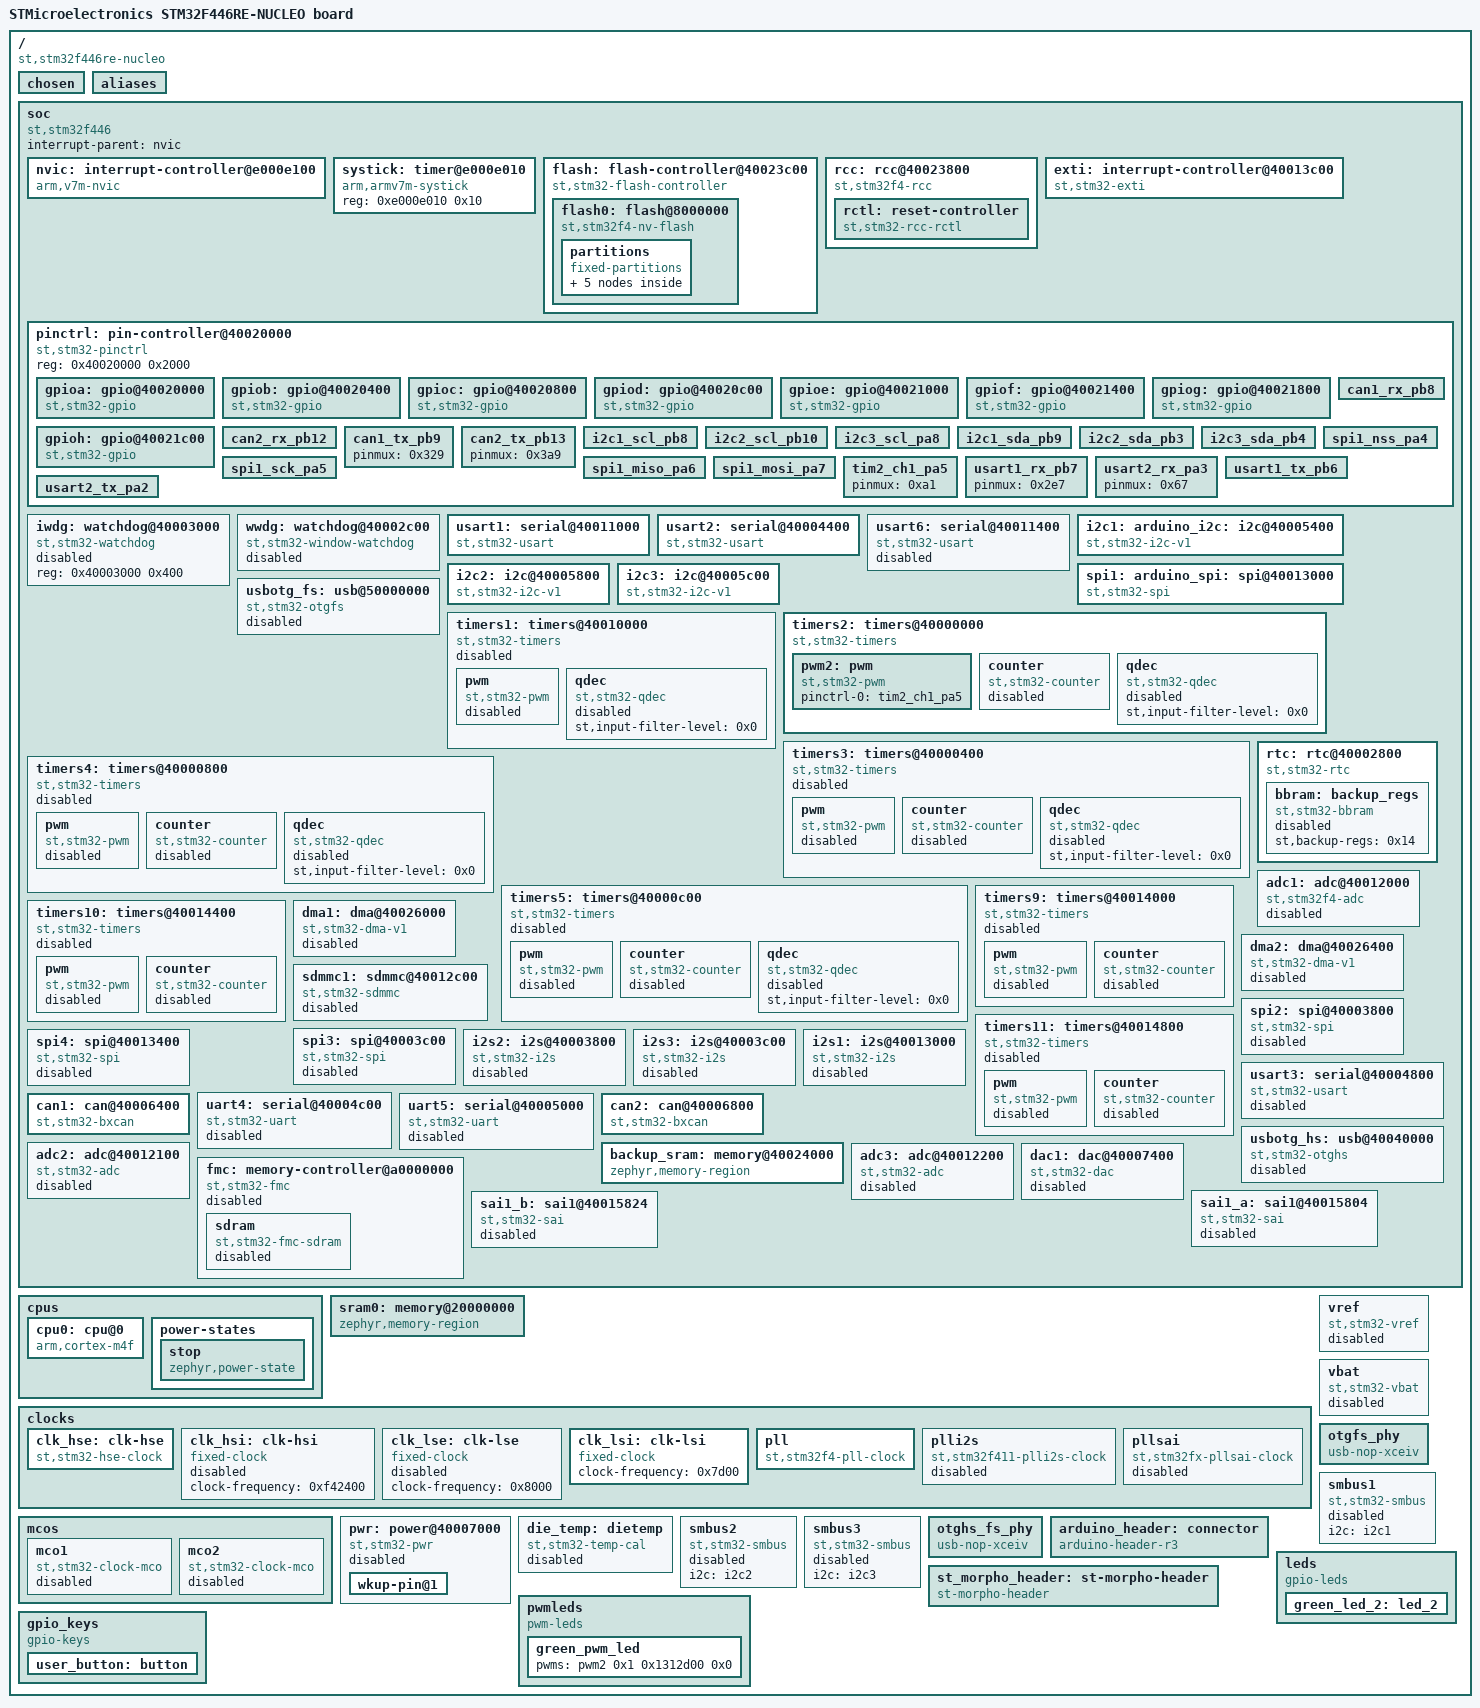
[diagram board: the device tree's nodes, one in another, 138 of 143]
/dts-v1/;

/* node '/' defined in zephyr\dts\common\skeleton.dtsi:9 */
/ {
	#address-cells = < 0x1 >;                              /* in zephyr\dts\common\skeleton.dtsi:10 */
	#size-cells = < 0x1 >;                                 /* in zephyr\dts\common\skeleton.dtsi:11 */
	model = "STMicroelectronics STM32F446RE-NUCLEO board"; /* in zephyr\boards\st\nucleo_f446re\nucleo_f446re.dts:15 */
	compatible = "st,stm32f446re-nucleo";                  /* in zephyr\boards\st\nucleo_f446re\nucleo_f446re.dts:16 */

	/* node '/chosen' defined in zephyr\dts\common\skeleton.dtsi:13 */
	chosen {
		zephyr,flash-controller = &flash;  /* in zephyr\dts\arm\st\f4\stm32f4.dtsi:27 */
		zephyr,cortex-m-idle-timer = &rtc; /* in zephyr\dts\arm\st\f4\stm32f4.dtsi:28 */
		zephyr,console = &usart2;          /* in zephyr\boards\st\nucleo_f446re\nucleo_f446re.dts:19 */
		zephyr,shell-uart = &usart2;       /* in zephyr\boards\st\nucleo_f446re\nucleo_f446re.dts:20 */
		zephyr,sram = &sram0;              /* in zephyr\boards\st\nucleo_f446re\nucleo_f446re.dts:21 */
		zephyr,flash = &flash0;            /* in zephyr\boards\st\nucleo_f446re\nucleo_f446re.dts:22 */
		zephyr,canbus = &can2;             /* in zephyr\boards\st\nucleo_f446re\nucleo_f446re.dts:23 */
	};

	/* node '/aliases' defined in zephyr\dts\common\skeleton.dtsi:15 */
	aliases {
		led0 = &green_led_2;       /* in zephyr\boards\st\nucleo_f446re\nucleo_f446re.dts:54 */
		pwm-led0 = &green_pwm_led; /* in zephyr\boards\st\nucleo_f446re\nucleo_f446re.dts:55 */
		sw0 = &user_button;        /* in zephyr\boards\st\nucleo_f446re\nucleo_f446re.dts:56 */
	};

	/* node '/soc' defined in zephyr\dts\arm\armv7-m.dtsi:6 */
	soc {
		#address-cells = < 0x1 >;     /* in zephyr\dts\arm\armv7-m.dtsi:7 */
		#size-cells = < 0x1 >;        /* in zephyr\dts\arm\armv7-m.dtsi:8 */
		interrupt-parent = < &nvic >; /* in zephyr\dts\arm\armv7-m.dtsi:10 */
		ranges;                       /* in zephyr\dts\arm\armv7-m.dtsi:11 */
		compatible = "st,stm32f446",
		             "st,stm32f4",
		             "simple-bus";    /* in zephyr\dts\arm\st\f4\stm32f446.dtsi:26 */

		/* node '/soc/interrupt-controller@e000e100' defined in zephyr\dts\arm\armv7-m.dtsi:13 */
		nvic: interrupt-controller@e000e100 {
			#address-cells = < 0x1 >;            /* in zephyr\dts\arm\armv7-m.dtsi:14 */
			compatible = "arm,v7m-nvic";         /* in zephyr\dts\arm\armv7-m.dtsi:15 */
			reg = < 0xe000e100 0xc00 >;          /* in zephyr\dts\arm\armv7-m.dtsi:16 */
			interrupt-controller;                /* in zephyr\dts\arm\armv7-m.dtsi:17 */
			#interrupt-cells = < 0x2 >;          /* in zephyr\dts\arm\armv7-m.dtsi:18 */
			arm,num-irq-priority-bits = < 0x4 >; /* in zephyr\dts\arm\st\f4\stm32f4.dtsi:676 */
			phandle = < 0x1 >;                   /* in zephyr\dts\arm\armv7-m.dtsi:10 */
		};

		/* node '/soc/timer@e000e010' defined in zephyr\dts\arm\armv7-m.dtsi:21 */
		systick: timer@e000e010 {
			compatible = "arm,armv7m-systick"; /* in zephyr\dts\arm\armv7-m.dtsi:22 */
			reg = < 0xe000e010 0x10 >;         /* in zephyr\dts\arm\armv7-m.dtsi:23 */
		};

		/* node '/soc/flash-controller@40023c00' defined in zephyr\dts\arm\st\f4\stm32f4.dtsi:111 */
		flash: flash-controller@40023c00 {
			compatible = "st,stm32-flash-controller",
			             "st,stm32f4-flash-controller"; /* in zephyr\dts\arm\st\f4\stm32f4.dtsi:112 */
			reg = < 0x40023c00 0x400 >;                 /* in zephyr\dts\arm\st\f4\stm32f4.dtsi:113 */
			interrupts = < 0x4 0x0 >;                   /* in zephyr\dts\arm\st\f4\stm32f4.dtsi:114 */
			#address-cells = < 0x1 >;                   /* in zephyr\dts\arm\st\f4\stm32f4.dtsi:116 */
			#size-cells = < 0x1 >;                      /* in zephyr\dts\arm\st\f4\stm32f4.dtsi:117 */

			/* node '/soc/flash-controller@40023c00/flash@8000000' defined in zephyr\dts\arm\st\f4\stm32f4.dtsi:119 */
			flash0: flash@8000000 {
				compatible = "st,stm32f4-nv-flash",
				             "st,stm32-nv-flash",
				             "soc-nv-flash";        /* in zephyr\dts\arm\st\f4\stm32f4.dtsi:120 */
				write-block-size = < 0x1 >;         /* in zephyr\dts\arm\st\f4\stm32f4.dtsi:123 */
				max-erase-time = < 0xfa0 >;         /* in zephyr\dts\arm\st\f4\stm32f4.dtsi:125 */
				reg = < 0x8000000 0x80000 >;        /* in zephyr\dts\arm\st\f4\stm32f446Xe.dtsi:17 */

				/* node '/soc/flash-controller@40023c00/flash@8000000/partitions' defined in zephyr\boards\st\nucleo_f446re\nucleo_f446re.dts:163 */
				partitions {
					compatible = "fixed-partitions"; /* in zephyr\boards\st\nucleo_f446re\nucleo_f446re.dts:164 */
					#address-cells = < 0x1 >;        /* in zephyr\boards\st\nucleo_f446re\nucleo_f446re.dts:165 */
					#size-cells = < 0x1 >;           /* in zephyr\boards\st\nucleo_f446re\nucleo_f446re.dts:166 */

					/* node '/soc/flash-controller@40023c00/flash@8000000/partitions/partition@0' defined in zephyr\boards\st\nucleo_f446re\nucleo_f446re.dts:168 */
					boot_partition: partition@0 {
						label = "mcuboot";     /* in zephyr\boards\st\nucleo_f446re\nucleo_f446re.dts:169 */
						reg = < 0x0 0x10000 >; /* in zephyr\boards\st\nucleo_f446re\nucleo_f446re.dts:170 */
						read-only;             /* in zephyr\boards\st\nucleo_f446re\nucleo_f446re.dts:171 */
					};

					/* node '/soc/flash-controller@40023c00/flash@8000000/partitions/partition@10000' defined in zephyr\boards\st\nucleo_f446re\nucleo_f446re.dts:179 */
					storage_partition: partition@10000 {
						label = "storage";         /* in zephyr\boards\st\nucleo_f446re\nucleo_f446re.dts:180 */
						reg = < 0x10000 0x10000 >; /* in zephyr\boards\st\nucleo_f446re\nucleo_f446re.dts:181 */
					};

					/* node '/soc/flash-controller@40023c00/flash@8000000/partitions/partition@20000' defined in zephyr\boards\st\nucleo_f446re\nucleo_f446re.dts:184 */
					slot0_partition: partition@20000 {
						label = "image-0";         /* in zephyr\boards\st\nucleo_f446re\nucleo_f446re.dts:185 */
						reg = < 0x20000 0x20000 >; /* in zephyr\boards\st\nucleo_f446re\nucleo_f446re.dts:186 */
					};

					/* node '/soc/flash-controller@40023c00/flash@8000000/partitions/partition@40000' defined in zephyr\boards\st\nucleo_f446re\nucleo_f446re.dts:189 */
					slot1_partition: partition@40000 {
						label = "image-1";         /* in zephyr\boards\st\nucleo_f446re\nucleo_f446re.dts:190 */
						reg = < 0x40000 0x20000 >; /* in zephyr\boards\st\nucleo_f446re\nucleo_f446re.dts:191 */
					};

					/* node '/soc/flash-controller@40023c00/flash@8000000/partitions/partition@60000' defined in zephyr\boards\st\nucleo_f446re\nucleo_f446re.dts:194 */
					scratch_partition: partition@60000 {
						label = "image-scratch";   /* in zephyr\boards\st\nucleo_f446re\nucleo_f446re.dts:195 */
						reg = < 0x60000 0x20000 >; /* in zephyr\boards\st\nucleo_f446re\nucleo_f446re.dts:196 */
					};
				};
			};
		};

		/* node '/soc/rcc@40023800' defined in zephyr\dts\arm\st\f4\stm32f4.dtsi:129 */
		rcc: rcc@40023800 {
			compatible = "st,stm32f4-rcc";   /* in zephyr\dts\arm\st\f4\stm32f4.dtsi:130 */
			#clock-cells = < 0x2 >;          /* in zephyr\dts\arm\st\f4\stm32f4.dtsi:131 */
			reg = < 0x40023800 0x400 >;      /* in zephyr\dts\arm\st\f4\stm32f4.dtsi:132 */
			clocks = < &pll >;               /* in agent\nucleo_f446re.overlay:18 */
			clock-frequency = < 0xaba9500 >; /* in agent\nucleo_f446re.overlay:20 */
			ahb-prescaler = < 0x1 >;         /* in agent\nucleo_f446re.overlay:23 */
			apb1-prescaler = < 0x4 >;        /* in agent\nucleo_f446re.overlay:24 */
			apb2-prescaler = < 0x2 >;        /* in agent\nucleo_f446re.overlay:25 */
			phandle = < 0x3 >;               /* in zephyr\dts\arm\st\f4\stm32f4.dtsi:146 */

			/* node '/soc/rcc@40023800/reset-controller' defined in zephyr\dts\arm\st\f4\stm32f4.dtsi:134 */
			rctl: reset-controller {
				compatible = "st,stm32-rcc-rctl"; /* in zephyr\dts\arm\st\f4\stm32f4.dtsi:135 */
				#reset-cells = < 0x1 >;           /* in zephyr\dts\arm\st\f4\stm32f4.dtsi:136 */
				phandle = < 0x4 >;                /* in zephyr\dts\arm\st\f4\stm32f4.dtsi:245 */
			};
		};

		/* node '/soc/interrupt-controller@40013c00' defined in zephyr\dts\arm\st\f4\stm32f4.dtsi:140 */
		exti: interrupt-controller@40013c00 {
			compatible = "st,stm32-exti";  /* in zephyr\dts\arm\st\f4\stm32f4.dtsi:141 */
			interrupt-controller;          /* in zephyr\dts\arm\st\f4\stm32f4.dtsi:142 */
			#interrupt-cells = < 0x1 >;    /* in zephyr\dts\arm\st\f4\stm32f4.dtsi:143 */
			#address-cells = < 0x0 >;      /* in zephyr\dts\arm\st\f4\stm32f4.dtsi:144 */
			reg = < 0x40013c00 0x400 >;    /* in zephyr\dts\arm\st\f4\stm32f4.dtsi:145 */
			clocks = < &rcc 0x44 0x4000 >; /* in zephyr\dts\arm\st\f4\stm32f4.dtsi:146 */
			num-lines = < 0x20 >;          /* in zephyr\dts\arm\st\f4\stm32f4.dtsi:147 */
			interrupts = < 0x6 0x0 >,
			             < 0x7 0x0 >,
			             < 0x8 0x0 >,
			             < 0x9 0x0 >,
			             < 0xa 0x0 >,
			             < 0x17 0x0 >,
			             < 0x28 0x0 >;     /* in zephyr\dts\arm\st\f4\stm32f4.dtsi:148 */
			interrupt-names = "line0",
			                  "line1",
			                  "line2",
			                  "line3",
			                  "line4",
			                  "line5-9",
			                  "line10-15"; /* in zephyr\dts\arm\st\f4\stm32f4.dtsi:150 */
			line-ranges = < 0x0 0x1 >,
			              < 0x1 0x1 >,
			              < 0x2 0x1 >,
			              < 0x3 0x1 >,
			              < 0x4 0x1 >,
			              < 0x5 0x5 >,
			              < 0xa 0x6 >;     /* in zephyr\dts\arm\st\f4\stm32f4.dtsi:152 */
		};

		/* node '/soc/pin-controller@40020000' defined in zephyr\dts\arm\st\f4\stm32f4.dtsi:156 */
		pinctrl: pin-controller@40020000 {
			compatible = "st,stm32-pinctrl"; /* in zephyr\dts\arm\st\f4\stm32f4.dtsi:157 */
			#address-cells = < 0x1 >;        /* in zephyr\dts\arm\st\f4\stm32f4.dtsi:158 */
			#size-cells = < 0x1 >;           /* in zephyr\dts\arm\st\f4\stm32f4.dtsi:159 */
			reg = < 0x40020000 0x2000 >;     /* in zephyr\dts\arm\st\f4\stm32f4.dtsi:160 */

			/* node '/soc/pin-controller@40020000/gpio@40020000' defined in zephyr\dts\arm\st\f4\stm32f4.dtsi:162 */
			gpioa: gpio@40020000 {
				compatible = "st,stm32-gpio"; /* in zephyr\dts\arm\st\f4\stm32f4.dtsi:163 */
				gpio-controller;              /* in zephyr\dts\arm\st\f4\stm32f4.dtsi:164 */
				#gpio-cells = < 0x2 >;        /* in zephyr\dts\arm\st\f4\stm32f4.dtsi:165 */
				reg = < 0x40020000 0x400 >;   /* in zephyr\dts\arm\st\f4\stm32f4.dtsi:166 */
				clocks = < &rcc 0x30 0x1 >;   /* in zephyr\dts\arm\st\f4\stm32f4.dtsi:167 */
				phandle = < 0x1e >;           /* in zephyr\dts\arm\st\f4\stm32f4.dtsi:615 */
			};

			/* node '/soc/pin-controller@40020000/gpio@40020400' defined in zephyr\dts\arm\st\f4\stm32f4.dtsi:170 */
			gpiob: gpio@40020400 {
				compatible = "st,stm32-gpio"; /* in zephyr\dts\arm\st\f4\stm32f4.dtsi:171 */
				gpio-controller;              /* in zephyr\dts\arm\st\f4\stm32f4.dtsi:172 */
				#gpio-cells = < 0x2 >;        /* in zephyr\dts\arm\st\f4\stm32f4.dtsi:173 */
				reg = < 0x40020400 0x400 >;   /* in zephyr\dts\arm\st\f4\stm32f4.dtsi:174 */
				clocks = < &rcc 0x30 0x2 >;   /* in zephyr\dts\arm\st\f4\stm32f4.dtsi:175 */
				phandle = < 0x23 >;           /* in zephyr\boards\st\nucleo_f446re\arduino_r3_connector.dtsi:15 */
			};

			/* node '/soc/pin-controller@40020000/gpio@40020800' defined in zephyr\dts\arm\st\f4\stm32f4.dtsi:178 */
			gpioc: gpio@40020800 {
				compatible = "st,stm32-gpio"; /* in zephyr\dts\arm\st\f4\stm32f4.dtsi:179 */
				gpio-controller;              /* in zephyr\dts\arm\st\f4\stm32f4.dtsi:180 */
				#gpio-cells = < 0x2 >;        /* in zephyr\dts\arm\st\f4\stm32f4.dtsi:181 */
				reg = < 0x40020800 0x400 >;   /* in zephyr\dts\arm\st\f4\stm32f4.dtsi:182 */
				clocks = < &rcc 0x30 0x4 >;   /* in zephyr\dts\arm\st\f4\stm32f4.dtsi:183 */
				phandle = < 0x24 >;           /* in zephyr\boards\st\nucleo_f446re\arduino_r3_connector.dtsi:15 */
			};

			/* node '/soc/pin-controller@40020000/gpio@40020c00' defined in zephyr\dts\arm\st\f4\stm32f4.dtsi:186 */
			gpiod: gpio@40020c00 {
				compatible = "st,stm32-gpio"; /* in zephyr\dts\arm\st\f4\stm32f4.dtsi:187 */
				gpio-controller;              /* in zephyr\dts\arm\st\f4\stm32f4.dtsi:188 */
				#gpio-cells = < 0x2 >;        /* in zephyr\dts\arm\st\f4\stm32f4.dtsi:189 */
				reg = < 0x40020c00 0x400 >;   /* in zephyr\dts\arm\st\f4\stm32f4.dtsi:190 */
				clocks = < &rcc 0x30 0x8 >;   /* in zephyr\dts\arm\st\f4\stm32f4.dtsi:191 */
				phandle = < 0x25 >;           /* in zephyr\boards\st\nucleo_f446re\st_morpho_connector.dtsi:15 */
			};

			/* node '/soc/pin-controller@40020000/gpio@40021000' defined in zephyr\dts\arm\st\f4\stm32f4.dtsi:194 */
			gpioe: gpio@40021000 {
				compatible = "st,stm32-gpio"; /* in zephyr\dts\arm\st\f4\stm32f4.dtsi:195 */
				gpio-controller;              /* in zephyr\dts\arm\st\f4\stm32f4.dtsi:196 */
				#gpio-cells = < 0x2 >;        /* in zephyr\dts\arm\st\f4\stm32f4.dtsi:197 */
				reg = < 0x40021000 0x400 >;   /* in zephyr\dts\arm\st\f4\stm32f4.dtsi:198 */
				clocks = < &rcc 0x30 0x10 >;  /* in zephyr\dts\arm\st\f4\stm32f4.dtsi:199 */
			};

			/* node '/soc/pin-controller@40020000/gpio@40021400' defined in zephyr\dts\arm\st\f4\stm32f4.dtsi:202 */
			gpiof: gpio@40021400 {
				compatible = "st,stm32-gpio"; /* in zephyr\dts\arm\st\f4\stm32f4.dtsi:203 */
				gpio-controller;              /* in zephyr\dts\arm\st\f4\stm32f4.dtsi:204 */
				#gpio-cells = < 0x2 >;        /* in zephyr\dts\arm\st\f4\stm32f4.dtsi:205 */
				reg = < 0x40021400 0x400 >;   /* in zephyr\dts\arm\st\f4\stm32f4.dtsi:206 */
				clocks = < &rcc 0x30 0x20 >;  /* in zephyr\dts\arm\st\f4\stm32f4.dtsi:207 */
			};

			/* node '/soc/pin-controller@40020000/gpio@40021800' defined in zephyr\dts\arm\st\f4\stm32f4.dtsi:210 */
			gpiog: gpio@40021800 {
				compatible = "st,stm32-gpio"; /* in zephyr\dts\arm\st\f4\stm32f4.dtsi:211 */
				gpio-controller;              /* in zephyr\dts\arm\st\f4\stm32f4.dtsi:212 */
				#gpio-cells = < 0x2 >;        /* in zephyr\dts\arm\st\f4\stm32f4.dtsi:213 */
				reg = < 0x40021800 0x400 >;   /* in zephyr\dts\arm\st\f4\stm32f4.dtsi:214 */
				clocks = < &rcc 0x30 0x40 >;  /* in zephyr\dts\arm\st\f4\stm32f4.dtsi:215 */
			};

			/* node '/soc/pin-controller@40020000/gpio@40021c00' defined in zephyr\dts\arm\st\f4\stm32f4.dtsi:218 */
			gpioh: gpio@40021c00 {
				compatible = "st,stm32-gpio"; /* in zephyr\dts\arm\st\f4\stm32f4.dtsi:219 */
				gpio-controller;              /* in zephyr\dts\arm\st\f4\stm32f4.dtsi:220 */
				#gpio-cells = < 0x2 >;        /* in zephyr\dts\arm\st\f4\stm32f4.dtsi:221 */
				reg = < 0x40021c00 0x400 >;   /* in zephyr\dts\arm\st\f4\stm32f4.dtsi:222 */
				clocks = < &rcc 0x30 0x80 >;  /* in zephyr\dts\arm\st\f4\stm32f4.dtsi:223 */
				phandle = < 0x26 >;           /* in zephyr\boards\st\nucleo_f446re\st_morpho_connector.dtsi:15 */
			};

			/* node '/soc/pin-controller@40020000/can1_rx_pb8' defined in modules\hal\stm32\dts\st\f4\stm32f446r(c-e)tx-pinctrl.dtsi:384 */
			can1_rx_pb8: can1_rx_pb8 {
				pinmux = < 0x309 >; /* in modules\hal\stm32\dts\st\f4\stm32f446r(c-e)tx-pinctrl.dtsi:385 */
				bias-pull-up;       /* in modules\hal\stm32\dts\st\f4\stm32f446r(c-e)tx-pinctrl.dtsi:386 */
				phandle = < 0x17 >; /* in zephyr\boards\st\nucleo_f446re\nucleo_f446re.dts:151 */
			};

			/* node '/soc/pin-controller@40020000/can2_rx_pb12' defined in modules\hal\stm32\dts\st\f4\stm32f446r(c-e)tx-pinctrl.dtsi:394 */
			can2_rx_pb12: can2_rx_pb12 {
				pinmux = < 0x389 >; /* in modules\hal\stm32\dts\st\f4\stm32f446r(c-e)tx-pinctrl.dtsi:395 */
				bias-pull-up;       /* in modules\hal\stm32\dts\st\f4\stm32f446r(c-e)tx-pinctrl.dtsi:396 */
				phandle = < 0x19 >; /* in zephyr\boards\st\nucleo_f446re\nucleo_f446re.dts:157 */
			};

			/* node '/soc/pin-controller@40020000/can1_tx_pb9' defined in modules\hal\stm32\dts\st\f4\stm32f446r(c-e)tx-pinctrl.dtsi:405 */
			can1_tx_pb9: can1_tx_pb9 {
				pinmux = < 0x329 >; /* in modules\hal\stm32\dts\st\f4\stm32f446r(c-e)tx-pinctrl.dtsi:406 */
				phandle = < 0x18 >; /* in zephyr\boards\st\nucleo_f446re\nucleo_f446re.dts:151 */
			};

			/* node '/soc/pin-controller@40020000/can2_tx_pb13' defined in modules\hal\stm32\dts\st\f4\stm32f446r(c-e)tx-pinctrl.dtsi:413 */
			can2_tx_pb13: can2_tx_pb13 {
				pinmux = < 0x3a9 >; /* in modules\hal\stm32\dts\st\f4\stm32f446r(c-e)tx-pinctrl.dtsi:414 */
				phandle = < 0x1a >; /* in zephyr\boards\st\nucleo_f446re\nucleo_f446re.dts:157 */
			};

			/* node '/soc/pin-controller@40020000/i2c1_scl_pb8' defined in modules\hal\stm32\dts\st\f4\stm32f446r(c-e)tx-pinctrl.dtsi:522 */
			i2c1_scl_pb8: i2c1_scl_pb8 {
				pinmux = < 0x304 >; /* in modules\hal\stm32\dts\st\f4\stm32f446r(c-e)tx-pinctrl.dtsi:523 */
				bias-pull-up;       /* in modules\hal\stm32\dts\st\f4\stm32f446r(c-e)tx-pinctrl.dtsi:524 */
				drive-open-drain;   /* in modules\hal\stm32\dts\st\f4\stm32f446r(c-e)tx-pinctrl.dtsi:525 */
				phandle = < 0x9 >;  /* in zephyr\boards\st\nucleo_f446re\nucleo_f446re.dts:102 */
			};

			/* node '/soc/pin-controller@40020000/i2c2_scl_pb10' defined in modules\hal\stm32\dts\st\f4\stm32f446r(c-e)tx-pinctrl.dtsi:528 */
			i2c2_scl_pb10: i2c2_scl_pb10 {
				pinmux = < 0x344 >; /* in modules\hal\stm32\dts\st\f4\stm32f446r(c-e)tx-pinctrl.dtsi:529 */
				bias-pull-up;       /* in modules\hal\stm32\dts\st\f4\stm32f446r(c-e)tx-pinctrl.dtsi:530 */
				drive-open-drain;   /* in modules\hal\stm32\dts\st\f4\stm32f446r(c-e)tx-pinctrl.dtsi:531 */
				phandle = < 0xb >;  /* in zephyr\boards\st\nucleo_f446re\nucleo_f446re.dts:109 */
			};

			/* node '/soc/pin-controller@40020000/i2c3_scl_pa8' defined in modules\hal\stm32\dts\st\f4\stm32f446r(c-e)tx-pinctrl.dtsi:534 */
			i2c3_scl_pa8: i2c3_scl_pa8 {
				pinmux = < 0x104 >; /* in modules\hal\stm32\dts\st\f4\stm32f446r(c-e)tx-pinctrl.dtsi:535 */
				bias-pull-up;       /* in modules\hal\stm32\dts\st\f4\stm32f446r(c-e)tx-pinctrl.dtsi:536 */
				drive-open-drain;   /* in modules\hal\stm32\dts\st\f4\stm32f446r(c-e)tx-pinctrl.dtsi:537 */
				phandle = < 0xd >;  /* in zephyr\boards\st\nucleo_f446re\nucleo_f446re.dts:116 */
			};

			/* node '/soc/pin-controller@40020000/i2c1_sda_pb9' defined in modules\hal\stm32\dts\st\f4\stm32f446r(c-e)tx-pinctrl.dtsi:548 */
			i2c1_sda_pb9: i2c1_sda_pb9 {
				pinmux = < 0x324 >; /* in modules\hal\stm32\dts\st\f4\stm32f446r(c-e)tx-pinctrl.dtsi:549 */
				bias-pull-up;       /* in modules\hal\stm32\dts\st\f4\stm32f446r(c-e)tx-pinctrl.dtsi:550 */
				drive-open-drain;   /* in modules\hal\stm32\dts\st\f4\stm32f446r(c-e)tx-pinctrl.dtsi:551 */
				phandle = < 0xa >;  /* in zephyr\boards\st\nucleo_f446re\nucleo_f446re.dts:102 */
			};

			/* node '/soc/pin-controller@40020000/i2c2_sda_pb3' defined in modules\hal\stm32\dts\st\f4\stm32f446r(c-e)tx-pinctrl.dtsi:554 */
			i2c2_sda_pb3: i2c2_sda_pb3 {
				pinmux = < 0x264 >; /* in modules\hal\stm32\dts\st\f4\stm32f446r(c-e)tx-pinctrl.dtsi:555 */
				bias-pull-up;       /* in modules\hal\stm32\dts\st\f4\stm32f446r(c-e)tx-pinctrl.dtsi:556 */
				drive-open-drain;   /* in modules\hal\stm32\dts\st\f4\stm32f446r(c-e)tx-pinctrl.dtsi:557 */
				phandle = < 0xc >;  /* in zephyr\boards\st\nucleo_f446re\nucleo_f446re.dts:109 */
			};

			/* node '/soc/pin-controller@40020000/i2c3_sda_pb4' defined in modules\hal\stm32\dts\st\f4\stm32f446r(c-e)tx-pinctrl.dtsi:566 */
			i2c3_sda_pb4: i2c3_sda_pb4 {
				pinmux = < 0x284 >; /* in modules\hal\stm32\dts\st\f4\stm32f446r(c-e)tx-pinctrl.dtsi:567 */
				bias-pull-up;       /* in modules\hal\stm32\dts\st\f4\stm32f446r(c-e)tx-pinctrl.dtsi:568 */
				drive-open-drain;   /* in modules\hal\stm32\dts\st\f4\stm32f446r(c-e)tx-pinctrl.dtsi:569 */
				phandle = < 0xe >;  /* in zephyr\boards\st\nucleo_f446re\nucleo_f446re.dts:116 */
			};

			/* node '/soc/pin-controller@40020000/spi1_miso_pa6' defined in modules\hal\stm32\dts\st\f4\stm32f446r(c-e)tx-pinctrl.dtsi:913 */
			spi1_miso_pa6: spi1_miso_pa6 {
				pinmux = < 0xc5 >;  /* in modules\hal\stm32\dts\st\f4\stm32f446r(c-e)tx-pinctrl.dtsi:914 */
				bias-pull-down;     /* in modules\hal\stm32\dts\st\f4\stm32f446r(c-e)tx-pinctrl.dtsi:915 */
				phandle = < 0x11 >; /* in zephyr\boards\st\nucleo_f446re\nucleo_f446re.dts:123 */
			};

			/* node '/soc/pin-controller@40020000/spi1_mosi_pa7' defined in modules\hal\stm32\dts\st\f4\stm32f446r(c-e)tx-pinctrl.dtsi:945 */
			spi1_mosi_pa7: spi1_mosi_pa7 {
				pinmux = < 0xe5 >;  /* in modules\hal\stm32\dts\st\f4\stm32f446r(c-e)tx-pinctrl.dtsi:946 */
				bias-pull-down;     /* in modules\hal\stm32\dts\st\f4\stm32f446r(c-e)tx-pinctrl.dtsi:947 */
				phandle = < 0x12 >; /* in zephyr\boards\st\nucleo_f446re\nucleo_f446re.dts:123 */
			};

			/* node '/soc/pin-controller@40020000/spi1_nss_pa4' defined in modules\hal\stm32\dts\st\f4\stm32f446r(c-e)tx-pinctrl.dtsi:997 */
			spi1_nss_pa4: spi1_nss_pa4 {
				pinmux = < 0x85 >; /* in modules\hal\stm32\dts\st\f4\stm32f446r(c-e)tx-pinctrl.dtsi:998 */
				bias-pull-up;      /* in modules\hal\stm32\dts\st\f4\stm32f446r(c-e)tx-pinctrl.dtsi:999 */
				phandle = < 0xf >; /* in zephyr\boards\st\nucleo_f446re\nucleo_f446re.dts:123 */
			};

			/* node '/soc/pin-controller@40020000/spi1_sck_pa5' defined in modules\hal\stm32\dts\st\f4\stm32f446r(c-e)tx-pinctrl.dtsi:1034 */
			spi1_sck_pa5: spi1_sck_pa5 {
				pinmux = < 0xa5 >;             /* in modules\hal\stm32\dts\st\f4\stm32f446r(c-e)tx-pinctrl.dtsi:1035 */
				bias-pull-down;                /* in modules\hal\stm32\dts\st\f4\stm32f446r(c-e)tx-pinctrl.dtsi:1036 */
				slew-rate = "very-high-speed"; /* in modules\hal\stm32\dts\st\f4\stm32f446r(c-e)tx-pinctrl.dtsi:1037 */
				phandle = < 0x10 >;            /* in zephyr\boards\st\nucleo_f446re\nucleo_f446re.dts:123 */
			};

			/* node '/soc/pin-controller@40020000/tim2_ch1_pa5' defined in modules\hal\stm32\dts\st\f4\stm32f446r(c-e)tx-pinctrl.dtsi:1162 */
			tim2_ch1_pa5: tim2_ch1_pa5 {
				pinmux = < 0xa1 >;  /* in modules\hal\stm32\dts\st\f4\stm32f446r(c-e)tx-pinctrl.dtsi:1163 */
				phandle = < 0x14 >; /* in zephyr\boards\st\nucleo_f446re\nucleo_f446re.dts:134 */
			};

			/* node '/soc/pin-controller@40020000/usart1_rx_pb7' defined in modules\hal\stm32\dts\st\f4\stm32f446r(c-e)tx-pinctrl.dtsi:1386 */
			usart1_rx_pb7: usart1_rx_pb7 {
				pinmux = < 0x2e7 >; /* in modules\hal\stm32\dts\st\f4\stm32f446r(c-e)tx-pinctrl.dtsi:1387 */
				phandle = < 0x6 >;  /* in zephyr\boards\st\nucleo_f446re\nucleo_f446re.dts:88 */
			};

			/* node '/soc/pin-controller@40020000/usart2_rx_pa3' defined in modules\hal\stm32\dts\st\f4\stm32f446r(c-e)tx-pinctrl.dtsi:1390 */
			usart2_rx_pa3: usart2_rx_pa3 {
				pinmux = < 0x67 >; /* in modules\hal\stm32\dts\st\f4\stm32f446r(c-e)tx-pinctrl.dtsi:1391 */
				phandle = < 0x8 >; /* in zephyr\boards\st\nucleo_f446re\nucleo_f446re.dts:95 */
			};

			/* node '/soc/pin-controller@40020000/usart1_tx_pb6' defined in modules\hal\stm32\dts\st\f4\stm32f446r(c-e)tx-pinctrl.dtsi:1425 */
			usart1_tx_pb6: usart1_tx_pb6 {
				pinmux = < 0x2c7 >; /* in modules\hal\stm32\dts\st\f4\stm32f446r(c-e)tx-pinctrl.dtsi:1426 */
				bias-pull-up;       /* in modules\hal\stm32\dts\st\f4\stm32f446r(c-e)tx-pinctrl.dtsi:1427 */
				phandle = < 0x5 >;  /* in zephyr\boards\st\nucleo_f446re\nucleo_f446re.dts:88 */
			};

			/* node '/soc/pin-controller@40020000/usart2_tx_pa2' defined in modules\hal\stm32\dts\st\f4\stm32f446r(c-e)tx-pinctrl.dtsi:1430 */
			usart2_tx_pa2: usart2_tx_pa2 {
				pinmux = < 0x47 >; /* in modules\hal\stm32\dts\st\f4\stm32f446r(c-e)tx-pinctrl.dtsi:1431 */
				bias-pull-up;      /* in modules\hal\stm32\dts\st\f4\stm32f446r(c-e)tx-pinctrl.dtsi:1432 */
				phandle = < 0x7 >; /* in zephyr\boards\st\nucleo_f446re\nucleo_f446re.dts:95 */
			};
		};

		/* node '/soc/watchdog@40003000' defined in zephyr\dts\arm\st\f4\stm32f4.dtsi:227 */
		iwdg: watchdog@40003000 {
			compatible = "st,stm32-watchdog"; /* in zephyr\dts\arm\st\f4\stm32f4.dtsi:228 */
			reg = < 0x40003000 0x400 >;       /* in zephyr\dts\arm\st\f4\stm32f4.dtsi:229 */
			status = "disabled";              /* in zephyr\dts\arm\st\f4\stm32f4.dtsi:230 */
		};

		/* node '/soc/watchdog@40002c00' defined in zephyr\dts\arm\st\f4\stm32f4.dtsi:233 */
		wwdg: watchdog@40002c00 {
			compatible = "st,stm32-window-watchdog"; /* in zephyr\dts\arm\st\f4\stm32f4.dtsi:234 */
			reg = < 0x40002c00 0x400 >;              /* in zephyr\dts\arm\st\f4\stm32f4.dtsi:235 */
			clocks = < &rcc 0x40 0x800 >;            /* in zephyr\dts\arm\st\f4\stm32f4.dtsi:236 */
			interrupts = < 0x0 0x7 >;                /* in zephyr\dts\arm\st\f4\stm32f4.dtsi:237 */
			status = "disabled";                     /* in zephyr\dts\arm\st\f4\stm32f4.dtsi:238 */
		};

		/* node '/soc/serial@40011000' defined in zephyr\dts\arm\st\f4\stm32f4.dtsi:241 */
		usart1: serial@40011000 {
			compatible = "st,stm32-usart",
			             "st,stm32-uart";                  /* in zephyr\dts\arm\st\f4\stm32f4.dtsi:242 */
			reg = < 0x40011000 0x400 >;                    /* in zephyr\dts\arm\st\f4\stm32f4.dtsi:243 */
			clocks = < &rcc 0x44 0x10 >;                   /* in zephyr\dts\arm\st\f4\stm32f4.dtsi:244 */
			resets = < &rctl 0x484 >;                      /* in zephyr\dts\arm\st\f4\stm32f4.dtsi:245 */
			interrupts = < 0x25 0x0 >;                     /* in zephyr\dts\arm\st\f4\stm32f4.dtsi:246 */
			pinctrl-0 = < &usart1_tx_pb6 &usart1_rx_pb7 >; /* in zephyr\boards\st\nucleo_f446re\nucleo_f446re.dts:88 */
			pinctrl-names = "default";                     /* in zephyr\boards\st\nucleo_f446re\nucleo_f446re.dts:89 */
			current-speed = < 0x1c200 >;                   /* in zephyr\boards\st\nucleo_f446re\nucleo_f446re.dts:90 */
			status = "okay";                               /* in zephyr\boards\st\nucleo_f446re\nucleo_f446re.dts:91 */
		};

		/* node '/soc/serial@40004400' defined in zephyr\dts\arm\st\f4\stm32f4.dtsi:250 */
		usart2: serial@40004400 {
			compatible = "st,stm32-usart",
			             "st,stm32-uart";                  /* in zephyr\dts\arm\st\f4\stm32f4.dtsi:251 */
			reg = < 0x40004400 0x400 >;                    /* in zephyr\dts\arm\st\f4\stm32f4.dtsi:252 */
			clocks = < &rcc 0x40 0x20000 >;                /* in zephyr\dts\arm\st\f4\stm32f4.dtsi:253 */
			resets = < &rctl 0x411 >;                      /* in zephyr\dts\arm\st\f4\stm32f4.dtsi:254 */
			interrupts = < 0x26 0x0 >;                     /* in zephyr\dts\arm\st\f4\stm32f4.dtsi:255 */
			pinctrl-0 = < &usart2_tx_pa2 &usart2_rx_pa3 >; /* in zephyr\boards\st\nucleo_f446re\nucleo_f446re.dts:95 */
			pinctrl-names = "default";                     /* in zephyr\boards\st\nucleo_f446re\nucleo_f446re.dts:96 */
			current-speed = < 0x1c200 >;                   /* in zephyr\boards\st\nucleo_f446re\nucleo_f446re.dts:97 */
			status = "okay";                               /* in zephyr\boards\st\nucleo_f446re\nucleo_f446re.dts:98 */
		};

		/* node '/soc/serial@40011400' defined in zephyr\dts\arm\st\f4\stm32f4.dtsi:259 */
		usart6: serial@40011400 {
			compatible = "st,stm32-usart",
			             "st,stm32-uart";  /* in zephyr\dts\arm\st\f4\stm32f4.dtsi:260 */
			reg = < 0x40011400 0x400 >;    /* in zephyr\dts\arm\st\f4\stm32f4.dtsi:261 */
			clocks = < &rcc 0x44 0x20 >;   /* in zephyr\dts\arm\st\f4\stm32f4.dtsi:262 */
			resets = < &rctl 0x485 >;      /* in zephyr\dts\arm\st\f4\stm32f4.dtsi:263 */
			interrupts = < 0x47 0x0 >;     /* in zephyr\dts\arm\st\f4\stm32f4.dtsi:264 */
			status = "disabled";           /* in zephyr\dts\arm\st\f4\stm32f4.dtsi:265 */
		};

		/* node '/soc/i2c@40005400' defined in zephyr\dts\arm\st\f4\stm32f4.dtsi:268 */
		i2c1: arduino_i2c: i2c@40005400 {
			compatible = "st,stm32-i2c-v1";              /* in zephyr\dts\arm\st\f4\stm32f4.dtsi:269 */
			#address-cells = < 0x1 >;                    /* in zephyr\dts\arm\st\f4\stm32f4.dtsi:271 */
			#size-cells = < 0x0 >;                       /* in zephyr\dts\arm\st\f4\stm32f4.dtsi:272 */
			reg = < 0x40005400 0x400 >;                  /* in zephyr\dts\arm\st\f4\stm32f4.dtsi:273 */
			clocks = < &rcc 0x40 0x200000 >;             /* in zephyr\dts\arm\st\f4\stm32f4.dtsi:274 */
			interrupts = < 0x1f 0x0 >,
			             < 0x20 0x0 >;                   /* in zephyr\dts\arm\st\f4\stm32f4.dtsi:275 */
			interrupt-names = "event",
			                  "error";                   /* in zephyr\dts\arm\st\f4\stm32f4.dtsi:276 */
			pinctrl-0 = < &i2c1_scl_pb8 &i2c1_sda_pb9 >; /* in zephyr\boards\st\nucleo_f446re\nucleo_f446re.dts:102 */
			pinctrl-names = "default";                   /* in zephyr\boards\st\nucleo_f446re\nucleo_f446re.dts:103 */
			status = "okay";                             /* in zephyr\boards\st\nucleo_f446re\nucleo_f446re.dts:104 */
			clock-frequency = < 0x61a80 >;               /* in zephyr\boards\st\nucleo_f446re\nucleo_f446re.dts:105 */
			phandle = < 0x20 >;                          /* in zephyr\dts\arm\st\f4\stm32f4.dtsi:654 */
		};

		/* node '/soc/i2c@40005800' defined in zephyr\dts\arm\st\f4\stm32f4.dtsi:280 */
		i2c2: i2c@40005800 {
			compatible = "st,stm32-i2c-v1";               /* in zephyr\dts\arm\st\f4\stm32f4.dtsi:281 */
			#address-cells = < 0x1 >;                     /* in zephyr\dts\arm\st\f4\stm32f4.dtsi:283 */
			#size-cells = < 0x0 >;                        /* in zephyr\dts\arm\st\f4\stm32f4.dtsi:284 */
			reg = < 0x40005800 0x400 >;                   /* in zephyr\dts\arm\st\f4\stm32f4.dtsi:285 */
			clocks = < &rcc 0x40 0x400000 >;              /* in zephyr\dts\arm\st\f4\stm32f4.dtsi:286 */
			interrupts = < 0x21 0x0 >,
			             < 0x22 0x0 >;                    /* in zephyr\dts\arm\st\f4\stm32f4.dtsi:287 */
			interrupt-names = "event",
			                  "error";                    /* in zephyr\dts\arm\st\f4\stm32f4.dtsi:288 */
			pinctrl-0 = < &i2c2_scl_pb10 &i2c2_sda_pb3 >; /* in zephyr\boards\st\nucleo_f446re\nucleo_f446re.dts:109 */
			pinctrl-names = "default";                    /* in zephyr\boards\st\nucleo_f446re\nucleo_f446re.dts:110 */
			status = "okay";                              /* in zephyr\boards\st\nucleo_f446re\nucleo_f446re.dts:111 */
			clock-frequency = < 0x61a80 >;                /* in zephyr\boards\st\nucleo_f446re\nucleo_f446re.dts:112 */
			phandle = < 0x21 >;                           /* in zephyr\dts\arm\st\f4\stm32f4.dtsi:662 */
		};

		/* node '/soc/i2c@40005c00' defined in zephyr\dts\arm\st\f4\stm32f4.dtsi:292 */
		i2c3: i2c@40005c00 {
			compatible = "st,stm32-i2c-v1";              /* in zephyr\dts\arm\st\f4\stm32f4.dtsi:293 */
			#address-cells = < 0x1 >;                    /* in zephyr\dts\arm\st\f4\stm32f4.dtsi:295 */
			#size-cells = < 0x0 >;                       /* in zephyr\dts\arm\st\f4\stm32f4.dtsi:296 */
			reg = < 0x40005c00 0x400 >;                  /* in zephyr\dts\arm\st\f4\stm32f4.dtsi:297 */
			clocks = < &rcc 0x40 0x800000 >;             /* in zephyr\dts\arm\st\f4\stm32f4.dtsi:298 */
			interrupts = < 0x48 0x0 >,
			             < 0x49 0x0 >;                   /* in zephyr\dts\arm\st\f4\stm32f4.dtsi:299 */
			interrupt-names = "event",
			                  "error";                   /* in zephyr\dts\arm\st\f4\stm32f4.dtsi:300 */
			pinctrl-0 = < &i2c3_scl_pa8 &i2c3_sda_pb4 >; /* in zephyr\boards\st\nucleo_f446re\nucleo_f446re.dts:116 */
			pinctrl-names = "default";                   /* in zephyr\boards\st\nucleo_f446re\nucleo_f446re.dts:117 */
			status = "okay";                             /* in zephyr\boards\st\nucleo_f446re\nucleo_f446re.dts:118 */
			clock-frequency = < 0x61a80 >;               /* in zephyr\boards\st\nucleo_f446re\nucleo_f446re.dts:119 */
			phandle = < 0x22 >;                          /* in zephyr\dts\arm\st\f4\stm32f4.dtsi:670 */
		};

		/* node '/soc/spi@40013000' defined in zephyr\dts\arm\st\f4\stm32f4.dtsi:304 */
		spi1: arduino_spi: spi@40013000 {
			compatible = "st,stm32-spi";                                               /* in zephyr\dts\arm\st\f4\stm32f4.dtsi:305 */
			#address-cells = < 0x1 >;                                                  /* in zephyr\dts\arm\st\f4\stm32f4.dtsi:306 */
			#size-cells = < 0x0 >;                                                     /* in zephyr\dts\arm\st\f4\stm32f4.dtsi:307 */
			reg = < 0x40013000 0x400 >;                                                /* in zephyr\dts\arm\st\f4\stm32f4.dtsi:308 */
			clocks = < &rcc 0x44 0x1000 >;                                             /* in zephyr\dts\arm\st\f4\stm32f4.dtsi:309 */
			interrupts = < 0x23 0x5 >;                                                 /* in zephyr\dts\arm\st\f4\stm32f4.dtsi:310 */
			pinctrl-0 = < &spi1_nss_pa4 &spi1_sck_pa5 &spi1_miso_pa6 &spi1_mosi_pa7 >; /* in zephyr\boards\st\nucleo_f446re\nucleo_f446re.dts:123 */
			pinctrl-names = "default";                                                 /* in zephyr\boards\st\nucleo_f446re\nucleo_f446re.dts:125 */
			status = "okay";                                                           /* in zephyr\boards\st\nucleo_f446re\nucleo_f446re.dts:126 */
		};

		/* node '/soc/usb@50000000' defined in zephyr\dts\arm\st\f4\stm32f4.dtsi:314 */
		usbotg_fs: usb@50000000 {
			compatible = "st,stm32-otgfs";  /* in zephyr\dts\arm\st\f4\stm32f4.dtsi:315 */
			reg = < 0x50000000 0x40000 >;   /* in zephyr\dts\arm\st\f4\stm32f4.dtsi:316 */
			interrupts = < 0x43 0x0 >;      /* in zephyr\dts\arm\st\f4\stm32f4.dtsi:317 */
			interrupt-names = "otgfs";      /* in zephyr\dts\arm\st\f4\stm32f4.dtsi:318 */
			ram-size = < 0x500 >;           /* in zephyr\dts\arm\st\f4\stm32f4.dtsi:320 */
			maximum-speed = "full-speed";   /* in zephyr\dts\arm\st\f4\stm32f4.dtsi:321 */
			phys = < &otgfs_phy >;          /* in zephyr\dts\arm\st\f4\stm32f4.dtsi:322 */
			status = "disabled";            /* in zephyr\dts\arm\st\f4\stm32f4.dtsi:325 */
			num-bidir-endpoints = < 0x6 >;  /* in zephyr\dts\arm\st\f4\stm32f446.dtsi:89 */
			clocks = < &rcc 0x34 0x80 >,
			         < &rcc 0x7 0x1b0094 >; /* in zephyr\dts\arm\st\f4\stm32f446.dtsi:90 */
		};

		/* node '/soc/timers@40010000' defined in zephyr\dts\arm\st\f4\stm32f4.dtsi:328 */
		timers1: timers@40010000 {
			compatible = "st,stm32-timers"; /* in zephyr\dts\arm\st\f4\stm32f4.dtsi:329 */
			reg = < 0x40010000 0x400 >;     /* in zephyr\dts\arm\st\f4\stm32f4.dtsi:330 */
			clocks = < &rcc 0x44 0x1 >,
			         < &rcc 0xd 0xff >;     /* in zephyr\dts\arm\st\f4\stm32f4.dtsi:331 */
			resets = < &rctl 0x480 >;       /* in zephyr\dts\arm\st\f4\stm32f4.dtsi:333 */
			interrupts = < 0x18 0x0 >,
			             < 0x19 0x0 >,
			             < 0x1a 0x0 >,
			             < 0x1b 0x0 >;      /* in zephyr\dts\arm\st\f4\stm32f4.dtsi:334 */
			interrupt-names = "brk",
			                  "up",
			                  "trgcom",
			                  "cc";         /* in zephyr\dts\arm\st\f4\stm32f4.dtsi:335 */
			st,prescaler = < 0x0 >;         /* in zephyr\dts\arm\st\f4\stm32f4.dtsi:336 */
			status = "disabled";            /* in zephyr\dts\arm\st\f4\stm32f4.dtsi:337 */

			/* node '/soc/timers@40010000/pwm' defined in zephyr\dts\arm\st\f4\stm32f4.dtsi:339 */
			pwm {
				compatible = "st,stm32-pwm"; /* in zephyr\dts\arm\st\f4\stm32f4.dtsi:340 */
				status = "disabled";         /* in zephyr\dts\arm\st\f4\stm32f4.dtsi:341 */
				#pwm-cells = < 0x3 >;        /* in zephyr\dts\arm\st\f4\stm32f4.dtsi:342 */
			};

			/* node '/soc/timers@40010000/qdec' defined in zephyr\dts\arm\st\f4\stm32f4.dtsi:345 */
			qdec {
				compatible = "st,stm32-qdec";    /* in zephyr\dts\arm\st\f4\stm32f4.dtsi:346 */
				st,input-filter-level = < 0x0 >; /* in zephyr\dts\arm\st\f4\stm32f4.dtsi:347 */
				status = "disabled";             /* in zephyr\dts\arm\st\f4\stm32f4.dtsi:348 */
			};
		};

		/* node '/soc/timers@40000000' defined in zephyr\dts\arm\st\f4\stm32f4.dtsi:352 */
		timers2: timers@40000000 {
			compatible = "st,stm32-timers"; /* in zephyr\dts\arm\st\f4\stm32f4.dtsi:353 */
			reg = < 0x40000000 0x400 >;     /* in zephyr\dts\arm\st\f4\stm32f4.dtsi:354 */
			clocks = < &rcc 0x40 0x1 >,
			         < &rcc 0xc 0xff >;     /* in zephyr\dts\arm\st\f4\stm32f4.dtsi:355 */
			resets = < &rctl 0x400 >;       /* in zephyr\dts\arm\st\f4\stm32f4.dtsi:357 */
			interrupts = < 0x1c 0x0 >;      /* in zephyr\dts\arm\st\f4\stm32f4.dtsi:358 */
			interrupt-names = "global";     /* in zephyr\dts\arm\st\f4\stm32f4.dtsi:359 */
			st,prescaler = < 0x0 >;         /* in zephyr\dts\arm\st\f4\stm32f4.dtsi:360 */
			status = "okay";                /* in zephyr\boards\st\nucleo_f446re\nucleo_f446re.dts:130 */

			/* node '/soc/timers@40000000/pwm' defined in zephyr\dts\arm\st\f4\stm32f4.dtsi:363 */
			pwm2: pwm {
				compatible = "st,stm32-pwm";   /* in zephyr\dts\arm\st\f4\stm32f4.dtsi:364 */
				#pwm-cells = < 0x3 >;          /* in zephyr\dts\arm\st\f4\stm32f4.dtsi:366 */
				status = "okay";               /* in zephyr\boards\st\nucleo_f446re\nucleo_f446re.dts:133 */
				pinctrl-0 = < &tim2_ch1_pa5 >; /* in zephyr\boards\st\nucleo_f446re\nucleo_f446re.dts:134 */
				pinctrl-names = "default";     /* in zephyr\boards\st\nucleo_f446re\nucleo_f446re.dts:135 */
				phandle = < 0x27 >;            /* in zephyr\boards\st\nucleo_f446re\nucleo_f446re.dts:39 */
			};

			/* node '/soc/timers@40000000/counter' defined in zephyr\dts\arm\st\f4\stm32f4.dtsi:369 */
			counter {
				compatible = "st,stm32-counter"; /* in zephyr\dts\arm\st\f4\stm32f4.dtsi:370 */
				status = "disabled";             /* in zephyr\dts\arm\st\f4\stm32f4.dtsi:371 */
			};

			/* node '/soc/timers@40000000/qdec' defined in zephyr\dts\arm\st\f4\stm32f4.dtsi:374 */
			qdec {
				compatible = "st,stm32-qdec";    /* in zephyr\dts\arm\st\f4\stm32f4.dtsi:375 */
				st,input-filter-level = < 0x0 >; /* in zephyr\dts\arm\st\f4\stm32f4.dtsi:376 */
				status = "disabled";             /* in zephyr\dts\arm\st\f4\stm32f4.dtsi:377 */
			};
		};

		/* node '/soc/timers@40000400' defined in zephyr\dts\arm\st\f4\stm32f4.dtsi:381 */
		timers3: timers@40000400 {
			compatible = "st,stm32-timers"; /* in zephyr\dts\arm\st\f4\stm32f4.dtsi:382 */
			reg = < 0x40000400 0x400 >;     /* in zephyr\dts\arm\st\f4\stm32f4.dtsi:383 */
			clocks = < &rcc 0x40 0x2 >,
			         < &rcc 0xc 0xff >;     /* in zephyr\dts\arm\st\f4\stm32f4.dtsi:384 */
			resets = < &rctl 0x401 >;       /* in zephyr\dts\arm\st\f4\stm32f4.dtsi:386 */
			interrupts = < 0x1d 0x0 >;      /* in zephyr\dts\arm\st\f4\stm32f4.dtsi:387 */
			interrupt-names = "global";     /* in zephyr\dts\arm\st\f4\stm32f4.dtsi:388 */
			st,prescaler = < 0x0 >;         /* in zephyr\dts\arm\st\f4\stm32f4.dtsi:389 */
			status = "disabled";            /* in zephyr\dts\arm\st\f4\stm32f4.dtsi:390 */

			/* node '/soc/timers@40000400/pwm' defined in zephyr\dts\arm\st\f4\stm32f4.dtsi:392 */
			pwm {
				compatible = "st,stm32-pwm"; /* in zephyr\dts\arm\st\f4\stm32f4.dtsi:393 */
				status = "disabled";         /* in zephyr\dts\arm\st\f4\stm32f4.dtsi:394 */
				#pwm-cells = < 0x3 >;        /* in zephyr\dts\arm\st\f4\stm32f4.dtsi:395 */
			};

			/* node '/soc/timers@40000400/counter' defined in zephyr\dts\arm\st\f4\stm32f4.dtsi:398 */
			counter {
				compatible = "st,stm32-counter"; /* in zephyr\dts\arm\st\f4\stm32f4.dtsi:399 */
				status = "disabled";             /* in zephyr\dts\arm\st\f4\stm32f4.dtsi:400 */
			};

			/* node '/soc/timers@40000400/qdec' defined in zephyr\dts\arm\st\f4\stm32f4.dtsi:403 */
			qdec {
				compatible = "st,stm32-qdec";    /* in zephyr\dts\arm\st\f4\stm32f4.dtsi:404 */
				st,input-filter-level = < 0x0 >; /* in zephyr\dts\arm\st\f4\stm32f4.dtsi:405 */
				status = "disabled";             /* in zephyr\dts\arm\st\f4\stm32f4.dtsi:406 */
			};
		};

		/* node '/soc/timers@40000800' defined in zephyr\dts\arm\st\f4\stm32f4.dtsi:410 */
		timers4: timers@40000800 {
			compatible = "st,stm32-timers"; /* in zephyr\dts\arm\st\f4\stm32f4.dtsi:411 */
			reg = < 0x40000800 0x400 >;     /* in zephyr\dts\arm\st\f4\stm32f4.dtsi:412 */
			clocks = < &rcc 0x40 0x4 >,
			         < &rcc 0xc 0xff >;     /* in zephyr\dts\arm\st\f4\stm32f4.dtsi:413 */
			resets = < &rctl 0x402 >;       /* in zephyr\dts\arm\st\f4\stm32f4.dtsi:415 */
			interrupts = < 0x1e 0x0 >;      /* in zephyr\dts\arm\st\f4\stm32f4.dtsi:416 */
			interrupt-names = "global";     /* in zephyr\dts\arm\st\f4\stm32f4.dtsi:417 */
			st,prescaler = < 0x0 >;         /* in zephyr\dts\arm\st\f4\stm32f4.dtsi:418 */
			status = "disabled";            /* in zephyr\dts\arm\st\f4\stm32f4.dtsi:419 */

			/* node '/soc/timers@40000800/pwm' defined in zephyr\dts\arm\st\f4\stm32f4.dtsi:421 */
			pwm {
				compatible = "st,stm32-pwm"; /* in zephyr\dts\arm\st\f4\stm32f4.dtsi:422 */
				status = "disabled";         /* in zephyr\dts\arm\st\f4\stm32f4.dtsi:423 */
				#pwm-cells = < 0x3 >;        /* in zephyr\dts\arm\st\f4\stm32f4.dtsi:424 */
			};

			/* node '/soc/timers@40000800/counter' defined in zephyr\dts\arm\st\f4\stm32f4.dtsi:427 */
			counter {
				compatible = "st,stm32-counter"; /* in zephyr\dts\arm\st\f4\stm32f4.dtsi:428 */
				status = "disabled";             /* in zephyr\dts\arm\st\f4\stm32f4.dtsi:429 */
			};

			/* node '/soc/timers@40000800/qdec' defined in zephyr\dts\arm\st\f4\stm32f4.dtsi:432 */
			qdec {
				compatible = "st,stm32-qdec";    /* in zephyr\dts\arm\st\f4\stm32f4.dtsi:433 */
				st,input-filter-level = < 0x0 >; /* in zephyr\dts\arm\st\f4\stm32f4.dtsi:434 */
				status = "disabled";             /* in zephyr\dts\arm\st\f4\stm32f4.dtsi:435 */
			};
		};

		/* node '/soc/timers@40000c00' defined in zephyr\dts\arm\st\f4\stm32f4.dtsi:439 */
		timers5: timers@40000c00 {
			compatible = "st,stm32-timers"; /* in zephyr\dts\arm\st\f4\stm32f4.dtsi:440 */
			reg = < 0x40000c00 0x400 >;     /* in zephyr\dts\arm\st\f4\stm32f4.dtsi:441 */
			clocks = < &rcc 0x40 0x8 >,
			         < &rcc 0xc 0xff >;     /* in zephyr\dts\arm\st\f4\stm32f4.dtsi:442 */
			resets = < &rctl 0x403 >;       /* in zephyr\dts\arm\st\f4\stm32f4.dtsi:444 */
			interrupts = < 0x32 0x0 >;      /* in zephyr\dts\arm\st\f4\stm32f4.dtsi:445 */
			interrupt-names = "global";     /* in zephyr\dts\arm\st\f4\stm32f4.dtsi:446 */
			st,prescaler = < 0x0 >;         /* in zephyr\dts\arm\st\f4\stm32f4.dtsi:447 */
			status = "disabled";            /* in zephyr\dts\arm\st\f4\stm32f4.dtsi:448 */

			/* node '/soc/timers@40000c00/pwm' defined in zephyr\dts\arm\st\f4\stm32f4.dtsi:450 */
			pwm {
				compatible = "st,stm32-pwm"; /* in zephyr\dts\arm\st\f4\stm32f4.dtsi:451 */
				status = "disabled";         /* in zephyr\dts\arm\st\f4\stm32f4.dtsi:452 */
				#pwm-cells = < 0x3 >;        /* in zephyr\dts\arm\st\f4\stm32f4.dtsi:453 */
			};

			/* node '/soc/timers@40000c00/counter' defined in zephyr\dts\arm\st\f4\stm32f4.dtsi:456 */
			counter {
				compatible = "st,stm32-counter"; /* in zephyr\dts\arm\st\f4\stm32f4.dtsi:457 */
				status = "disabled";             /* in zephyr\dts\arm\st\f4\stm32f4.dtsi:458 */
			};

			/* node '/soc/timers@40000c00/qdec' defined in zephyr\dts\arm\st\f4\stm32f4.dtsi:461 */
			qdec {
				compatible = "st,stm32-qdec";    /* in zephyr\dts\arm\st\f4\stm32f4.dtsi:462 */
				st,input-filter-level = < 0x0 >; /* in zephyr\dts\arm\st\f4\stm32f4.dtsi:463 */
				status = "disabled";             /* in zephyr\dts\arm\st\f4\stm32f4.dtsi:464 */
			};
		};

		/* node '/soc/timers@40014000' defined in zephyr\dts\arm\st\f4\stm32f4.dtsi:468 */
		timers9: timers@40014000 {
			compatible = "st,stm32-timers"; /* in zephyr\dts\arm\st\f4\stm32f4.dtsi:469 */
			reg = < 0x40014000 0x400 >;     /* in zephyr\dts\arm\st\f4\stm32f4.dtsi:470 */
			clocks = < &rcc 0x44 0x10000 >,
			         < &rcc 0xd 0xff >;     /* in zephyr\dts\arm\st\f4\stm32f4.dtsi:471 */
			resets = < &rctl 0x490 >;       /* in zephyr\dts\arm\st\f4\stm32f4.dtsi:473 */
			interrupts = < 0x18 0x0 >;      /* in zephyr\dts\arm\st\f4\stm32f4.dtsi:474 */
			interrupt-names = "global";     /* in zephyr\dts\arm\st\f4\stm32f4.dtsi:475 */
			st,prescaler = < 0x0 >;         /* in zephyr\dts\arm\st\f4\stm32f4.dtsi:476 */
			status = "disabled";            /* in zephyr\dts\arm\st\f4\stm32f4.dtsi:477 */

			/* node '/soc/timers@40014000/pwm' defined in zephyr\dts\arm\st\f4\stm32f4.dtsi:479 */
			pwm {
				compatible = "st,stm32-pwm"; /* in zephyr\dts\arm\st\f4\stm32f4.dtsi:480 */
				status = "disabled";         /* in zephyr\dts\arm\st\f4\stm32f4.dtsi:481 */
				#pwm-cells = < 0x3 >;        /* in zephyr\dts\arm\st\f4\stm32f4.dtsi:482 */
			};

			/* node '/soc/timers@40014000/counter' defined in zephyr\dts\arm\st\f4\stm32f4.dtsi:485 */
			counter {
				compatible = "st,stm32-counter"; /* in zephyr\dts\arm\st\f4\stm32f4.dtsi:486 */
				status = "disabled";             /* in zephyr\dts\arm\st\f4\stm32f4.dtsi:487 */
			};
		};

		/* node '/soc/timers@40014400' defined in zephyr\dts\arm\st\f4\stm32f4.dtsi:491 */
		timers10: timers@40014400 {
			compatible = "st,stm32-timers"; /* in zephyr\dts\arm\st\f4\stm32f4.dtsi:492 */
			reg = < 0x40014400 0x400 >;     /* in zephyr\dts\arm\st\f4\stm32f4.dtsi:493 */
			clocks = < &rcc 0x44 0x20000 >,
			         < &rcc 0xd 0xff >;     /* in zephyr\dts\arm\st\f4\stm32f4.dtsi:494 */
			resets = < &rctl 0x491 >;       /* in zephyr\dts\arm\st\f4\stm32f4.dtsi:496 */
			interrupts = < 0x19 0x0 >;      /* in zephyr\dts\arm\st\f4\stm32f4.dtsi:497 */
			interrupt-names = "global";     /* in zephyr\dts\arm\st\f4\stm32f4.dtsi:498 */
			st,prescaler = < 0x0 >;         /* in zephyr\dts\arm\st\f4\stm32f4.dtsi:499 */
			status = "disabled";            /* in zephyr\dts\arm\st\f4\stm32f4.dtsi:500 */

			/* node '/soc/timers@40014400/pwm' defined in zephyr\dts\arm\st\f4\stm32f4.dtsi:502 */
			pwm {
				compatible = "st,stm32-pwm"; /* in zephyr\dts\arm\st\f4\stm32f4.dtsi:503 */
				status = "disabled";         /* in zephyr\dts\arm\st\f4\stm32f4.dtsi:504 */
				#pwm-cells = < 0x3 >;        /* in zephyr\dts\arm\st\f4\stm32f4.dtsi:505 */
			};

			/* node '/soc/timers@40014400/counter' defined in zephyr\dts\arm\st\f4\stm32f4.dtsi:508 */
			counter {
				compatible = "st,stm32-counter"; /* in zephyr\dts\arm\st\f4\stm32f4.dtsi:509 */
				status = "disabled";             /* in zephyr\dts\arm\st\f4\stm32f4.dtsi:510 */
			};
		};

		/* node '/soc/timers@40014800' defined in zephyr\dts\arm\st\f4\stm32f4.dtsi:514 */
		timers11: timers@40014800 {
			compatible = "st,stm32-timers"; /* in zephyr\dts\arm\st\f4\stm32f4.dtsi:515 */
			reg = < 0x40014800 0x400 >;     /* in zephyr\dts\arm\st\f4\stm32f4.dtsi:516 */
			clocks = < &rcc 0x44 0x40000 >,
			         < &rcc 0xd 0xff >;     /* in zephyr\dts\arm\st\f4\stm32f4.dtsi:517 */
			resets = < &rctl 0x492 >;       /* in zephyr\dts\arm\st\f4\stm32f4.dtsi:519 */
			interrupts = < 0x1a 0x0 >;      /* in zephyr\dts\arm\st\f4\stm32f4.dtsi:520 */
			interrupt-names = "global";     /* in zephyr\dts\arm\st\f4\stm32f4.dtsi:521 */
			st,prescaler = < 0x0 >;         /* in zephyr\dts\arm\st\f4\stm32f4.dtsi:522 */
			status = "disabled";            /* in zephyr\dts\arm\st\f4\stm32f4.dtsi:523 */

			/* node '/soc/timers@40014800/pwm' defined in zephyr\dts\arm\st\f4\stm32f4.dtsi:525 */
			pwm {
				compatible = "st,stm32-pwm"; /* in zephyr\dts\arm\st\f4\stm32f4.dtsi:526 */
				status = "disabled";         /* in zephyr\dts\arm\st\f4\stm32f4.dtsi:527 */
				#pwm-cells = < 0x3 >;        /* in zephyr\dts\arm\st\f4\stm32f4.dtsi:528 */
			};

			/* node '/soc/timers@40014800/counter' defined in zephyr\dts\arm\st\f4\stm32f4.dtsi:531 */
			counter {
				compatible = "st,stm32-counter"; /* in zephyr\dts\arm\st\f4\stm32f4.dtsi:532 */
				status = "disabled";             /* in zephyr\dts\arm\st\f4\stm32f4.dtsi:533 */
			};
		};

		/* node '/soc/rtc@40002800' defined in zephyr\dts\arm\st\f4\stm32f4.dtsi:537 */
		rtc: rtc@40002800 {
			compatible = "st,stm32-rtc";       /* in zephyr\dts\arm\st\f4\stm32f4.dtsi:538 */
			reg = < 0x40002800 0x400 >;        /* in zephyr\dts\arm\st\f4\stm32f4.dtsi:539 */
			interrupts = < 0x29 0x0 >;         /* in zephyr\dts\arm\st\f4\stm32f4.dtsi:540 */
			prescaler = < 0x8000 >;            /* in zephyr\dts\arm\st\f4\stm32f4.dtsi:542 */
			alarms-count = < 0x2 >;            /* in zephyr\dts\arm\st\f4\stm32f4.dtsi:543 */
			alrm-exti-line = < 0x11 >;         /* in zephyr\dts\arm\st\f4\stm32f4.dtsi:544 */
			clocks = < &rcc 0x40 0x10000000 >,
			         < &rcc 0x3 0x2280070 >;   /* in zephyr\boards\st\nucleo_f446re\nucleo_f446re.dts:140 */
			status = "okay";                   /* in zephyr\boards\st\nucleo_f446re\nucleo_f446re.dts:142 */

			/* node '/soc/rtc@40002800/backup_regs' defined in zephyr\dts\arm\st\f4\stm32f4.dtsi:547 */
			bbram: backup_regs {
				compatible = "st,stm32-bbram"; /* in zephyr\dts\arm\st\f4\stm32f4.dtsi:548 */
				st,backup-regs = < 0x14 >;     /* in zephyr\dts\arm\st\f4\stm32f4.dtsi:549 */
				status = "disabled";           /* in zephyr\dts\arm\st\f4\stm32f4.dtsi:550 */
			};
		};

		/* node '/soc/adc@40012000' defined in zephyr\dts\arm\st\f4\stm32f4.dtsi:554 */
		adc1: adc@40012000 {
			compatible = "st,stm32f4-adc",
			             "st,stm32-adc";                                 /* in zephyr\dts\arm\st\f4\stm32f4.dtsi:555 */
			reg = < 0x40012000 0x400 >;                                  /* in zephyr\dts\arm\st\f4\stm32f4.dtsi:556 */
			clocks = < &rcc 0x44 0x100 >;                                /* in zephyr\dts\arm\st\f4\stm32f4.dtsi:557 */
			clock-names = "adcx";                                        /* in zephyr\dts\arm\st\f4\stm32f4.dtsi:558 */
			interrupts = < 0x12 0x0 >;                                   /* in zephyr\dts\arm\st\f4\stm32f4.dtsi:559 */
			#io-channel-cells = < 0x1 >;                                 /* in zephyr\dts\arm\st\f4\stm32f4.dtsi:560 */
			resolutions = < 0x607804 0x517804 0x427804 0x337804 >;       /* in zephyr\dts\arm\st\f4\stm32f4.dtsi:561 */
			sampling-times = < 0x3 0xf 0x1c 0x38 0x54 0x70 0x90 0x1e0 >; /* in zephyr\dts\arm\st\f4\stm32f4.dtsi:565 */
			st,adc-clock-source = "SYNC";                                /* in zephyr\dts\arm\st\f4\stm32f4.dtsi:566 */
			st,adc-sequencer = "programmable";                           /* in zephyr\dts\arm\st\f4\stm32f4.dtsi:567 */
			st,adc-oversampler = "none";                                 /* in zephyr\dts\arm\st\f4\stm32f4.dtsi:568 */
			st,adc-internal-regulator = "none";                          /* in zephyr\dts\arm\st\f4\stm32f4.dtsi:569 */
			status = "disabled";                                         /* in zephyr\dts\arm\st\f4\stm32f4.dtsi:570 */
			phandle = < 0x1f >;                                          /* in zephyr\dts\arm\st\f4\stm32f446.dtsi:200 */
		};

		/* node '/soc/dma@40026000' defined in zephyr\dts\arm\st\f4\stm32f4.dtsi:573 */
		dma1: dma@40026000 {
			compatible = "st,stm32-dma-v1";                                                      /* in zephyr\dts\arm\st\f4\stm32f4.dtsi:574 */
			#dma-cells = < 0x4 >;                                                                /* in zephyr\dts\arm\st\f4\stm32f4.dtsi:575 */
			reg = < 0x40026000 0x400 >;                                                          /* in zephyr\dts\arm\st\f4\stm32f4.dtsi:576 */
			interrupts = < 0xb 0x0 0xc 0x0 0xd 0x0 0xe 0x0 0xf 0x0 0x10 0x0 0x11 0x0 0x2f 0x0 >; /* in zephyr\dts\arm\st\f4\stm32f4.dtsi:577 */
			clocks = < &rcc 0x30 0x200000 >;                                                     /* in zephyr\dts\arm\st\f4\stm32f4.dtsi:578 */
			status = "disabled";                                                                 /* in zephyr\dts\arm\st\f4\stm32f4.dtsi:579 */
			phandle = < 0x15 >;                                                                  /* in zephyr\dts\arm\st\f4\stm32f401.dtsi:58 */
		};

		/* node '/soc/dma@40026400' defined in zephyr\dts\arm\st\f4\stm32f4.dtsi:582 */
		dma2: dma@40026400 {
			compatible = "st,stm32-dma-v1";                                                           /* in zephyr\dts\arm\st\f4\stm32f4.dtsi:583 */
			#dma-cells = < 0x4 >;                                                                     /* in zephyr\dts\arm\st\f4\stm32f4.dtsi:584 */
			reg = < 0x40026400 0x400 >;                                                               /* in zephyr\dts\arm\st\f4\stm32f4.dtsi:585 */
			interrupts = < 0x38 0x0 0x39 0x0 0x3a 0x0 0x3b 0x0 0x3c 0x0 0x44 0x0 0x45 0x0 0x46 0x0 >; /* in zephyr\dts\arm\st\f4\stm32f4.dtsi:586 */
			clocks = < &rcc 0x30 0x400000 >;                                                          /* in zephyr\dts\arm\st\f4\stm32f4.dtsi:587 */
			st,mem2mem;                                                                               /* in zephyr\dts\arm\st\f4\stm32f4.dtsi:588 */
			status = "disabled";                                                                      /* in zephyr\dts\arm\st\f4\stm32f4.dtsi:589 */
			phandle = < 0x16 >;                                                                       /* in zephyr\dts\arm\st\f4\stm32f446.dtsi:35 */
		};

		/* node '/soc/sdmmc@40012c00' defined in zephyr\dts\arm\st\f4\stm32f4.dtsi:592 */
		sdmmc1: sdmmc@40012c00 {
			compatible = "st,stm32-sdmmc"; /* in zephyr\dts\arm\st\f4\stm32f4.dtsi:593 */
			reg = < 0x40012c00 0x400 >;    /* in zephyr\dts\arm\st\f4\stm32f4.dtsi:594 */
			clocks = < &rcc 0x44 0x800 >,
			         < &rcc 0x7 0xff >;    /* in zephyr\dts\arm\st\f4\stm32f4.dtsi:595 */
			resets = < &rctl 0x48b >;      /* in zephyr\dts\arm\st\f4\stm32f4.dtsi:597 */
			interrupts = < 0x31 0x0 >;     /* in zephyr\dts\arm\st\f4\stm32f4.dtsi:598 */
			status = "disabled";           /* in zephyr\dts\arm\st\f4\stm32f4.dtsi:599 */
		};

		/* node '/soc/spi@40003800' defined in zephyr\dts\arm\st\f4\stm32f401.dtsi:21 */
		spi2: spi@40003800 {
			compatible = "st,stm32-spi";   /* in zephyr\dts\arm\st\f4\stm32f401.dtsi:22 */
			#address-cells = < 0x1 >;      /* in zephyr\dts\arm\st\f4\stm32f401.dtsi:23 */
			#size-cells = < 0x0 >;         /* in zephyr\dts\arm\st\f4\stm32f401.dtsi:24 */
			reg = < 0x40003800 0x400 >;    /* in zephyr\dts\arm\st\f4\stm32f401.dtsi:25 */
			clocks = < &rcc 0x40 0x4000 >; /* in zephyr\dts\arm\st\f4\stm32f401.dtsi:26 */
			interrupts = < 0x24 0x5 >;     /* in zephyr\dts\arm\st\f4\stm32f401.dtsi:27 */
			status = "disabled";           /* in zephyr\dts\arm\st\f4\stm32f401.dtsi:28 */
		};

		/* node '/soc/spi@40003c00' defined in zephyr\dts\arm\st\f4\stm32f401.dtsi:31 */
		spi3: spi@40003c00 {
			compatible = "st,stm32-spi";   /* in zephyr\dts\arm\st\f4\stm32f401.dtsi:32 */
			#address-cells = < 0x1 >;      /* in zephyr\dts\arm\st\f4\stm32f401.dtsi:33 */
			#size-cells = < 0x0 >;         /* in zephyr\dts\arm\st\f4\stm32f401.dtsi:34 */
			reg = < 0x40003c00 0x400 >;    /* in zephyr\dts\arm\st\f4\stm32f401.dtsi:35 */
			clocks = < &rcc 0x40 0x8000 >; /* in zephyr\dts\arm\st\f4\stm32f401.dtsi:36 */
			interrupts = < 0x33 0x5 >;     /* in zephyr\dts\arm\st\f4\stm32f401.dtsi:37 */
			status = "disabled";           /* in zephyr\dts\arm\st\f4\stm32f401.dtsi:38 */
		};

		/* node '/soc/spi@40013400' defined in zephyr\dts\arm\st\f4\stm32f401.dtsi:41 */
		spi4: spi@40013400 {
			compatible = "st,stm32-spi";   /* in zephyr\dts\arm\st\f4\stm32f401.dtsi:42 */
			#address-cells = < 0x1 >;      /* in zephyr\dts\arm\st\f4\stm32f401.dtsi:43 */
			#size-cells = < 0x0 >;         /* in zephyr\dts\arm\st\f4\stm32f401.dtsi:44 */
			reg = < 0x40013400 0x400 >;    /* in zephyr\dts\arm\st\f4\stm32f401.dtsi:45 */
			clocks = < &rcc 0x44 0x2000 >; /* in zephyr\dts\arm\st\f4\stm32f401.dtsi:46 */
			interrupts = < 0x54 0x5 >;     /* in zephyr\dts\arm\st\f4\stm32f401.dtsi:47 */
			status = "disabled";           /* in zephyr\dts\arm\st\f4\stm32f401.dtsi:48 */
		};

		/* node '/soc/i2s@40003800' defined in zephyr\dts\arm\st\f4\stm32f401.dtsi:51 */
		i2s2: i2s@40003800 {
			compatible = "st,stm32-i2s";        /* in zephyr\dts\arm\st\f4\stm32f401.dtsi:52 */
			#address-cells = < 0x1 >;           /* in zephyr\dts\arm\st\f4\stm32f401.dtsi:53 */
			#size-cells = < 0x0 >;              /* in zephyr\dts\arm\st\f4\stm32f401.dtsi:54 */
			reg = < 0x40003800 0x400 >;         /* in zephyr\dts\arm\st\f4\stm32f401.dtsi:55 */
			clocks = < &rcc 0x40 0x4000 >;      /* in zephyr\dts\arm\st\f4\stm32f401.dtsi:56 */
			interrupts = < 0x24 0x5 >;          /* in zephyr\dts\arm\st\f4\stm32f401.dtsi:57 */
			dmas = < &dma1 0x4 0x0 0x400 0x3 >,
			       < &dma1 0x3 0x0 0x400 0x3 >; /* in zephyr\dts\arm\st\f4\stm32f401.dtsi:58 */
			dma-names = "tx",
			            "rx";                   /* in zephyr\dts\arm\st\f4\stm32f401.dtsi:60 */
			status = "disabled";                /* in zephyr\dts\arm\st\f4\stm32f401.dtsi:61 */
		};

		/* node '/soc/i2s@40003c00' defined in zephyr\dts\arm\st\f4\stm32f401.dtsi:64 */
		i2s3: i2s@40003c00 {
			compatible = "st,stm32-i2s";        /* in zephyr\dts\arm\st\f4\stm32f401.dtsi:65 */
			#address-cells = < 0x1 >;           /* in zephyr\dts\arm\st\f4\stm32f401.dtsi:66 */
			#size-cells = < 0x0 >;              /* in zephyr\dts\arm\st\f4\stm32f401.dtsi:67 */
			reg = < 0x40003c00 0x400 >;         /* in zephyr\dts\arm\st\f4\stm32f401.dtsi:68 */
			clocks = < &rcc 0x40 0x8000 >;      /* in zephyr\dts\arm\st\f4\stm32f401.dtsi:69 */
			interrupts = < 0x33 0x5 >;          /* in zephyr\dts\arm\st\f4\stm32f401.dtsi:70 */
			dmas = < &dma1 0x5 0x0 0x400 0x3 >,
			       < &dma1 0x0 0x0 0x400 0x3 >; /* in zephyr\dts\arm\st\f4\stm32f401.dtsi:71 */
			dma-names = "tx",
			            "rx";                   /* in zephyr\dts\arm\st\f4\stm32f401.dtsi:73 */
			status = "disabled";                /* in zephyr\dts\arm\st\f4\stm32f401.dtsi:74 */
		};

		/* node '/soc/i2s@40013000' defined in zephyr\dts\arm\st\f4\stm32f446.dtsi:28 */
		i2s1: i2s@40013000 {
			compatible = "st,stm32-i2s";        /* in zephyr\dts\arm\st\f4\stm32f446.dtsi:29 */
			#address-cells = < 0x1 >;           /* in zephyr\dts\arm\st\f4\stm32f446.dtsi:30 */
			#size-cells = < 0x0 >;              /* in zephyr\dts\arm\st\f4\stm32f446.dtsi:31 */
			reg = < 0x40013000 0x400 >;         /* in zephyr\dts\arm\st\f4\stm32f446.dtsi:32 */
			clocks = < &rcc 0x44 0x1000 >;      /* in zephyr\dts\arm\st\f4\stm32f446.dtsi:33 */
			interrupts = < 0x23 0x5 >;          /* in zephyr\dts\arm\st\f4\stm32f446.dtsi:34 */
			dmas = < &dma2 0x3 0x3 0x400 0x3 >,
			       < &dma2 0x2 0x3 0x400 0x3 >; /* in zephyr\dts\arm\st\f4\stm32f446.dtsi:35 */
			dma-names = "tx",
			            "rx";                   /* in zephyr\dts\arm\st\f4\stm32f446.dtsi:37 */
			status = "disabled";                /* in zephyr\dts\arm\st\f4\stm32f446.dtsi:38 */
		};

		/* node '/soc/serial@40004800' defined in zephyr\dts\arm\st\f4\stm32f446.dtsi:41 */
		usart3: serial@40004800 {
			compatible = "st,stm32-usart",
			             "st,stm32-uart";   /* in zephyr\dts\arm\st\f4\stm32f446.dtsi:42 */
			reg = < 0x40004800 0x400 >;     /* in zephyr\dts\arm\st\f4\stm32f446.dtsi:43 */
			clocks = < &rcc 0x40 0x40000 >; /* in zephyr\dts\arm\st\f4\stm32f446.dtsi:44 */
			resets = < &rctl 0x412 >;       /* in zephyr\dts\arm\st\f4\stm32f446.dtsi:45 */
			interrupts = < 0x27 0x0 >;      /* in zephyr\dts\arm\st\f4\stm32f446.dtsi:46 */
			status = "disabled";            /* in zephyr\dts\arm\st\f4\stm32f446.dtsi:47 */
		};

		/* node '/soc/serial@40004c00' defined in zephyr\dts\arm\st\f4\stm32f446.dtsi:50 */
		uart4: serial@40004c00 {
			compatible = "st,stm32-uart";   /* in zephyr\dts\arm\st\f4\stm32f446.dtsi:51 */
			reg = < 0x40004c00 0x400 >;     /* in zephyr\dts\arm\st\f4\stm32f446.dtsi:52 */
			clocks = < &rcc 0x40 0x80000 >; /* in zephyr\dts\arm\st\f4\stm32f446.dtsi:53 */
			resets = < &rctl 0x413 >;       /* in zephyr\dts\arm\st\f4\stm32f446.dtsi:54 */
			interrupts = < 0x34 0x0 >;      /* in zephyr\dts\arm\st\f4\stm32f446.dtsi:55 */
			status = "disabled";            /* in zephyr\dts\arm\st\f4\stm32f446.dtsi:56 */
		};

		/* node '/soc/serial@40005000' defined in zephyr\dts\arm\st\f4\stm32f446.dtsi:59 */
		uart5: serial@40005000 {
			compatible = "st,stm32-uart";    /* in zephyr\dts\arm\st\f4\stm32f446.dtsi:60 */
			reg = < 0x40005000 0x400 >;      /* in zephyr\dts\arm\st\f4\stm32f446.dtsi:61 */
			clocks = < &rcc 0x40 0x100000 >; /* in zephyr\dts\arm\st\f4\stm32f446.dtsi:62 */
			resets = < &rctl 0x414 >;        /* in zephyr\dts\arm\st\f4\stm32f446.dtsi:63 */
			interrupts = < 0x35 0x0 >;       /* in zephyr\dts\arm\st\f4\stm32f446.dtsi:64 */
			status = "disabled";             /* in zephyr\dts\arm\st\f4\stm32f446.dtsi:65 */
		};

		/* node '/soc/can@40006400' defined in zephyr\dts\arm\st\f4\stm32f446.dtsi:68 */
		can1: can@40006400 {
			compatible = "st,stm32-bxcan";             /* in zephyr\dts\arm\st\f4\stm32f446.dtsi:69 */
			reg = < 0x40006400 0x400 >;                /* in zephyr\dts\arm\st\f4\stm32f446.dtsi:70 */
			interrupts = < 0x13 0x0 >,
			             < 0x14 0x0 >,
			             < 0x15 0x0 >,
			             < 0x16 0x0 >;                 /* in zephyr\dts\arm\st\f4\stm32f446.dtsi:71 */
			interrupt-names = "TX",
			                  "RX0",
			                  "RX1",
			                  "SCE";                   /* in zephyr\dts\arm\st\f4\stm32f446.dtsi:72 */
			clocks = < &rcc 0x40 0x2000000 >;          /* in zephyr\dts\arm\st\f4\stm32f446.dtsi:73 */
			pinctrl-0 = < &can1_rx_pb8 &can1_tx_pb9 >; /* in zephyr\boards\st\nucleo_f446re\nucleo_f446re.dts:151 */
			pinctrl-names = "default";                 /* in zephyr\boards\st\nucleo_f446re\nucleo_f446re.dts:152 */
			status = "okay";                           /* in zephyr\boards\st\nucleo_f446re\nucleo_f446re.dts:153 */
		};

		/* node '/soc/can@40006800' defined in zephyr\dts\arm\st\f4\stm32f446.dtsi:77 */
		can2: can@40006800 {
			compatible = "st,stm32-bxcan";               /* in zephyr\dts\arm\st\f4\stm32f446.dtsi:78 */
			reg = < 0x40006800 0x400 >;                  /* in zephyr\dts\arm\st\f4\stm32f446.dtsi:79 */
			interrupts = < 0x3f 0x0 >,
			             < 0x40 0x0 >,
			             < 0x41 0x0 >,
			             < 0x42 0x0 >;                   /* in zephyr\dts\arm\st\f4\stm32f446.dtsi:80 */
			interrupt-names = "TX",
			                  "RX0",
			                  "RX1",
			                  "SCE";                     /* in zephyr\dts\arm\st\f4\stm32f446.dtsi:81 */
			clocks = < &rcc 0x40 0x6000000 >;            /* in zephyr\dts\arm\st\f4\stm32f446.dtsi:83 */
			master-can-reg = < 0x40006400 >;             /* in zephyr\dts\arm\st\f4\stm32f446.dtsi:84 */
			pinctrl-0 = < &can2_rx_pb12 &can2_tx_pb13 >; /* in zephyr\boards\st\nucleo_f446re\nucleo_f446re.dts:157 */
			pinctrl-names = "default";                   /* in zephyr\boards\st\nucleo_f446re\nucleo_f446re.dts:158 */
			status = "okay";                             /* in zephyr\boards\st\nucleo_f446re\nucleo_f446re.dts:159 */
		};

		/* node '/soc/usb@40040000' defined in zephyr\dts\arm\st\f4\stm32f446.dtsi:94 */
		usbotg_hs: usb@40040000 {
			compatible = "st,stm32-otghs";     /* in zephyr\dts\arm\st\f4\stm32f446.dtsi:95 */
			reg = < 0x40040000 0x40000 >;      /* in zephyr\dts\arm\st\f4\stm32f446.dtsi:96 */
			interrupts = < 0x4d 0x0 >,
			             < 0x4a 0x0 >,
			             < 0x4b 0x0 >;         /* in zephyr\dts\arm\st\f4\stm32f446.dtsi:97 */
			interrupt-names = "otghs",
			                  "ep1_out",
			                  "ep1_in";        /* in zephyr\dts\arm\st\f4\stm32f446.dtsi:98 */
			num-bidir-endpoints = < 0x9 >;     /* in zephyr\dts\arm\st\f4\stm32f446.dtsi:99 */
			ram-size = < 0x1000 >;             /* in zephyr\dts\arm\st\f4\stm32f446.dtsi:100 */
			maximum-speed = "full-speed";      /* in zephyr\dts\arm\st\f4\stm32f446.dtsi:101 */
			phys = < &otghs_fs_phy >;          /* in zephyr\dts\arm\st\f4\stm32f446.dtsi:102 */
			clocks = < &rcc 0x30 0x20000000 >,
			         < &rcc 0x7 0x1b0094 >;    /* in zephyr\dts\arm\st\f4\stm32f446.dtsi:103 */
			status = "disabled";               /* in zephyr\dts\arm\st\f4\stm32f446.dtsi:105 */
		};

		/* node '/soc/memory@40024000' defined in zephyr\dts\arm\st\f4\stm32f446.dtsi:108 */
		backup_sram: memory@40024000 {
			compatible = "zephyr,memory-region",
			             "st,stm32-backup-sram";  /* in zephyr\dts\arm\st\f4\stm32f446.dtsi:109 */
			reg = < 0x40024000 0x1000 >;          /* in zephyr\dts\arm\st\f4\stm32f446.dtsi:110 */
			clocks = < &rcc 0x30 0x40000 >;       /* in zephyr\dts\arm\st\f4\stm32f446.dtsi:111 */
			zephyr,memory-region = "BACKUP_SRAM"; /* in zephyr\dts\arm\st\f4\stm32f446.dtsi:112 */
			status = "okay";                      /* in zephyr\boards\st\nucleo_f446re\nucleo_f446re.dts:146 */
		};

		/* node '/soc/adc@40012100' defined in zephyr\dts\arm\st\f4\stm32f446.dtsi:116 */
		adc2: adc@40012100 {
			compatible = "st,stm32-adc";                                 /* in zephyr\dts\arm\st\f4\stm32f446.dtsi:117 */
			reg = < 0x40012100 0x50 >;                                   /* in zephyr\dts\arm\st\f4\stm32f446.dtsi:118 */
			clocks = < &rcc 0x44 0x200 >;                                /* in zephyr\dts\arm\st\f4\stm32f446.dtsi:119 */
			clock-names = "adcx";                                        /* in zephyr\dts\arm\st\f4\stm32f446.dtsi:120 */
			interrupts = < 0x12 0x0 >;                                   /* in zephyr\dts\arm\st\f4\stm32f446.dtsi:121 */
			#io-channel-cells = < 0x1 >;                                 /* in zephyr\dts\arm\st\f4\stm32f446.dtsi:122 */
			resolutions = < 0x607804 0x517804 0x427804 0x337804 >;       /* in zephyr\dts\arm\st\f4\stm32f446.dtsi:123 */
			sampling-times = < 0x3 0xf 0x1c 0x38 0x54 0x70 0x90 0x1e0 >; /* in zephyr\dts\arm\st\f4\stm32f446.dtsi:127 */
			st,adc-clock-source = "SYNC";                                /* in zephyr\dts\arm\st\f4\stm32f446.dtsi:128 */
			st,adc-sequencer = "programmable";                           /* in zephyr\dts\arm\st\f4\stm32f446.dtsi:129 */
			st,adc-oversampler = "none";                                 /* in zephyr\dts\arm\st\f4\stm32f446.dtsi:130 */
			st,adc-internal-regulator = "none";                          /* in zephyr\dts\arm\st\f4\stm32f446.dtsi:131 */
			status = "disabled";                                         /* in zephyr\dts\arm\st\f4\stm32f446.dtsi:132 */
		};

		/* node '/soc/adc@40012200' defined in zephyr\dts\arm\st\f4\stm32f446.dtsi:135 */
		adc3: adc@40012200 {
			compatible = "st,stm32-adc";                                 /* in zephyr\dts\arm\st\f4\stm32f446.dtsi:136 */
			reg = < 0x40012200 0x50 >;                                   /* in zephyr\dts\arm\st\f4\stm32f446.dtsi:137 */
			clocks = < &rcc 0x44 0x400 >;                                /* in zephyr\dts\arm\st\f4\stm32f446.dtsi:138 */
			clock-names = "adcx";                                        /* in zephyr\dts\arm\st\f4\stm32f446.dtsi:139 */
			interrupts = < 0x12 0x0 >;                                   /* in zephyr\dts\arm\st\f4\stm32f446.dtsi:140 */
			#io-channel-cells = < 0x1 >;                                 /* in zephyr\dts\arm\st\f4\stm32f446.dtsi:141 */
			resolutions = < 0x607804 0x517804 0x427804 0x337804 >;       /* in zephyr\dts\arm\st\f4\stm32f446.dtsi:142 */
			sampling-times = < 0x3 0xf 0x1c 0x38 0x54 0x70 0x90 0x1e0 >; /* in zephyr\dts\arm\st\f4\stm32f446.dtsi:146 */
			st,adc-clock-source = "SYNC";                                /* in zephyr\dts\arm\st\f4\stm32f446.dtsi:147 */
			st,adc-sequencer = "programmable";                           /* in zephyr\dts\arm\st\f4\stm32f446.dtsi:148 */
			st,adc-oversampler = "none";                                 /* in zephyr\dts\arm\st\f4\stm32f446.dtsi:149 */
			st,adc-internal-regulator = "none";                          /* in zephyr\dts\arm\st\f4\stm32f446.dtsi:150 */
			status = "disabled";                                         /* in zephyr\dts\arm\st\f4\stm32f446.dtsi:151 */
		};

		/* node '/soc/dac@40007400' defined in zephyr\dts\arm\st\f4\stm32f446.dtsi:154 */
		dac1: dac@40007400 {
			compatible = "st,stm32-dac";       /* in zephyr\dts\arm\st\f4\stm32f446.dtsi:155 */
			reg = < 0x40007400 0x400 >;        /* in zephyr\dts\arm\st\f4\stm32f446.dtsi:156 */
			clocks = < &rcc 0x40 0x20000000 >; /* in zephyr\dts\arm\st\f4\stm32f446.dtsi:157 */
			status = "disabled";               /* in zephyr\dts\arm\st\f4\stm32f446.dtsi:158 */
			#io-channel-cells = < 0x1 >;       /* in zephyr\dts\arm\st\f4\stm32f446.dtsi:159 */
		};

		/* node '/soc/memory-controller@a0000000' defined in zephyr\dts\arm\st\f4\stm32f446.dtsi:162 */
		fmc: memory-controller@a0000000 {
			compatible = "st,stm32-fmc"; /* in zephyr\dts\arm\st\f4\stm32f446.dtsi:163 */
			reg = < 0xa0000000 0x400 >;  /* in zephyr\dts\arm\st\f4\stm32f446.dtsi:164 */
			clocks = < &rcc 0x38 0x1 >;  /* in zephyr\dts\arm\st\f4\stm32f446.dtsi:165 */
			status = "disabled";         /* in zephyr\dts\arm\st\f4\stm32f446.dtsi:166 */

			/* node '/soc/memory-controller@a0000000/sdram' defined in zephyr\dts\arm\st\f4\stm32f446.dtsi:168 */
			sdram: sdram {
				compatible = "st,stm32-fmc-sdram"; /* in zephyr\dts\arm\st\f4\stm32f446.dtsi:169 */
				#address-cells = < 0x1 >;          /* in zephyr\dts\arm\st\f4\stm32f446.dtsi:170 */
				#size-cells = < 0x0 >;             /* in zephyr\dts\arm\st\f4\stm32f446.dtsi:171 */
				status = "disabled";               /* in zephyr\dts\arm\st\f4\stm32f446.dtsi:172 */
			};
		};

		/* node '/soc/sai1@40015804' defined in zephyr\dts\arm\st\f4\stm32f446.dtsi:176 */
		sai1_a: sai1@40015804 {
			compatible = "st,stm32-sai";          /* in zephyr\dts\arm\st\f4\stm32f446.dtsi:177 */
			#address-cells = < 0x1 >;             /* in zephyr\dts\arm\st\f4\stm32f446.dtsi:178 */
			#size-cells = < 0x0 >;                /* in zephyr\dts\arm\st\f4\stm32f446.dtsi:179 */
			reg = < 0x40015804 0x20 >;            /* in zephyr\dts\arm\st\f4\stm32f446.dtsi:180 */
			clocks = < &rcc 0x44 0x400000 >;      /* in zephyr\dts\arm\st\f4\stm32f446.dtsi:181 */
			dmas = < &dma2 0x1 0x0 0x22800 0x0 >; /* in zephyr\dts\arm\st\f4\stm32f446.dtsi:182 */
			status = "disabled";                  /* in zephyr\dts\arm\st\f4\stm32f446.dtsi:184 */
		};

		/* node '/soc/sai1@40015824' defined in zephyr\dts\arm\st\f4\stm32f446.dtsi:187 */
		sai1_b: sai1@40015824 {
			compatible = "st,stm32-sai";          /* in zephyr\dts\arm\st\f4\stm32f446.dtsi:188 */
			#address-cells = < 0x1 >;             /* in zephyr\dts\arm\st\f4\stm32f446.dtsi:189 */
			#size-cells = < 0x0 >;                /* in zephyr\dts\arm\st\f4\stm32f446.dtsi:190 */
			reg = < 0x40015824 0x20 >;            /* in zephyr\dts\arm\st\f4\stm32f446.dtsi:191 */
			clocks = < &rcc 0x44 0x400000 >;      /* in zephyr\dts\arm\st\f4\stm32f446.dtsi:192 */
			dmas = < &dma2 0x5 0x0 0x22800 0x0 >; /* in zephyr\dts\arm\st\f4\stm32f446.dtsi:193 */
			status = "disabled";                  /* in zephyr\dts\arm\st\f4\stm32f446.dtsi:195 */
		};
	};

	/* node '/cpus' defined in zephyr\dts\arm\st\f4\stm32f4.dtsi:31 */
	cpus {
		#address-cells = < 0x1 >; /* in zephyr\dts\arm\st\f4\stm32f4.dtsi:32 */
		#size-cells = < 0x0 >;    /* in zephyr\dts\arm\st\f4\stm32f4.dtsi:33 */

		/* node '/cpus/cpu@0' defined in zephyr\dts\arm\st\f4\stm32f4.dtsi:35 */
		cpu0: cpu@0 {
			device_type = "cpu";           /* in zephyr\dts\arm\st\f4\stm32f4.dtsi:36 */
			compatible = "arm,cortex-m4f"; /* in zephyr\dts\arm\st\f4\stm32f4.dtsi:37 */
			reg = < 0x0 >;                 /* in zephyr\dts\arm\st\f4\stm32f4.dtsi:38 */
			cpu-power-states = < &stop >;  /* in zephyr\dts\arm\st\f4\stm32f4.dtsi:39 */
		};

		/* node '/cpus/power-states' defined in zephyr\dts\arm\st\f4\stm32f4.dtsi:42 */
		power-states {

			/* node '/cpus/power-states/stop' defined in zephyr\dts\arm\st\f4\stm32f4.dtsi:43 */
			stop: stop {
				compatible = "zephyr,power-state";    /* in zephyr\dts\arm\st\f4\stm32f4.dtsi:44 */
				power-state-name = "suspend-to-idle"; /* in zephyr\dts\arm\st\f4\stm32f4.dtsi:45 */
				min-residency-us = < 0x190 >;         /* in zephyr\dts\arm\st\f4\stm32f4.dtsi:52 */
				exit-latency-us = < 0x12c >;          /* in zephyr\dts\arm\st\f4\stm32f4.dtsi:53 */
				phandle = < 0x1c >;                   /* in zephyr\dts\arm\st\f4\stm32f4.dtsi:39 */
			};
		};
	};

	/* node '/memory@20000000' defined in zephyr\dts\arm\st\f4\stm32f4.dtsi:58 */
	sram0: memory@20000000 {
		compatible = "zephyr,memory-region",
		             "mmio-sram";            /* in zephyr\dts\arm\st\f4\stm32f4.dtsi:59 */
		zephyr,memory-region = "SRAM0";      /* in zephyr\dts\arm\st\f4\stm32f4.dtsi:60 */
		reg = < 0x20000000 0x20000 >;        /* in zephyr\dts\arm\st\f4\stm32f446Xe.dtsi:11 */
	};

	/* node '/clocks' defined in zephyr\dts\arm\st\f4\stm32f4.dtsi:63 */
	clocks {

		/* node '/clocks/clk-hse' defined in zephyr\dts\arm\st\f4\stm32f4.dtsi:64 */
		clk_hse: clk-hse {
			#clock-cells = < 0x0 >;            /* in zephyr\dts\arm\st\f4\stm32f4.dtsi:65 */
			compatible = "st,stm32-hse-clock"; /* in zephyr\dts\arm\st\f4\stm32f4.dtsi:66 */
			hse-bypass;                        /* in zephyr\boards\st\nucleo_f446re\nucleo_f446re.dts:65 */
			clock-frequency = < 0x7a1200 >;    /* in zephyr\boards\st\nucleo_f446re\nucleo_f446re.dts:66 */
			status = "okay";                   /* in zephyr\boards\st\nucleo_f446re\nucleo_f446re.dts:67 */
			phandle = < 0x1d >;                /* in agent\nucleo_f446re.overlay:13 */
		};

		/* node '/clocks/clk-hsi' defined in zephyr\dts\arm\st\f4\stm32f4.dtsi:70 */
		clk_hsi: clk-hsi {
			#clock-cells = < 0x0 >;         /* in zephyr\dts\arm\st\f4\stm32f4.dtsi:71 */
			compatible = "fixed-clock";     /* in zephyr\dts\arm\st\f4\stm32f4.dtsi:72 */
			clock-frequency = < 0xf42400 >; /* in zephyr\dts\arm\st\f4\stm32f4.dtsi:73 */
			status = "disabled";            /* in zephyr\dts\arm\st\f4\stm32f4.dtsi:74 */
		};

		/* node '/clocks/clk-lse' defined in zephyr\dts\arm\st\f4\stm32f4.dtsi:77 */
		clk_lse: clk-lse {
			#clock-cells = < 0x0 >;       /* in zephyr\dts\arm\st\f4\stm32f4.dtsi:78 */
			compatible = "fixed-clock";   /* in zephyr\dts\arm\st\f4\stm32f4.dtsi:79 */
			clock-frequency = < 0x8000 >; /* in zephyr\dts\arm\st\f4\stm32f4.dtsi:80 */
			status = "disabled";          /* in zephyr\dts\arm\st\f4\stm32f4.dtsi:81 */
		};

		/* node '/clocks/clk-lsi' defined in zephyr\dts\arm\st\f4\stm32f4.dtsi:84 */
		clk_lsi: clk-lsi {
			#clock-cells = < 0x0 >;       /* in zephyr\dts\arm\st\f4\stm32f4.dtsi:85 */
			compatible = "fixed-clock";   /* in zephyr\dts\arm\st\f4\stm32f4.dtsi:86 */
			clock-frequency = < 0x7d00 >; /* in zephyr\dts\arm\st\f4\stm32f4.dtsi:87 */
			status = "okay";              /* in zephyr\boards\st\nucleo_f446re\nucleo_f446re.dts:61 */
		};

		/* node '/clocks/pll' defined in zephyr\dts\arm\st\f4\stm32f4.dtsi:91 */
		pll: pll {
			#clock-cells = < 0x0 >;              /* in zephyr\dts\arm\st\f4\stm32f4.dtsi:92 */
			compatible = "st,stm32f4-pll-clock"; /* in zephyr\dts\arm\st\f4\stm32f4.dtsi:93 */
			div-m = < 0x8 >;                     /* in agent\nucleo_f446re.overlay:8 */
			mul-n = < 0x168 >;                   /* in agent\nucleo_f446re.overlay:9 */
			div-p = < 0x2 >;                     /* in agent\nucleo_f446re.overlay:10 */
			div-q = < 0x7 >;                     /* in agent\nucleo_f446re.overlay:12 */
			clocks = < &clk_hse >;               /* in agent\nucleo_f446re.overlay:13 */
			status = "okay";                     /* in agent\nucleo_f446re.overlay:14 */
			phandle = < 0x2 >;                   /* in agent\nucleo_f446re.overlay:18 */
		};

		/* node '/clocks/plli2s' defined in zephyr\dts\arm\st\f4\stm32f401.dtsi:11 */
		plli2s: plli2s {
			#clock-cells = < 0x0 >;                   /* in zephyr\dts\arm\st\f4\stm32f401.dtsi:12 */
			status = "disabled";                      /* in zephyr\dts\arm\st\f4\stm32f401.dtsi:14 */
			compatible = "st,stm32f411-plli2s-clock"; /* in zephyr\dts\arm\st\f4\stm32f446.dtsi:15 */
		};

		/* node '/clocks/pllsai' defined in zephyr\dts\arm\st\f4\stm32f446.dtsi:18 */
		pllsai: pllsai {
			compatible = "st,stm32fx-pllsai-clock"; /* in zephyr\dts\arm\st\f4\stm32f446.dtsi:19 */
			#clock-cells = < 0x0 >;                 /* in zephyr\dts\arm\st\f4\stm32f446.dtsi:20 */
			status = "disabled";                    /* in zephyr\dts\arm\st\f4\stm32f446.dtsi:21 */
		};
	};

	/* node '/mcos' defined in zephyr\dts\arm\st\f4\stm32f4.dtsi:98 */
	mcos {

		/* node '/mcos/mco1' defined in zephyr\dts\arm\st\f4\stm32f4.dtsi:99 */
		mco1: mco1 {
			compatible = "st,stm32-clock-mco"; /* in zephyr\dts\arm\st\f4\stm32f4.dtsi:100 */
			status = "disabled";               /* in zephyr\dts\arm\st\f4\stm32f4.dtsi:101 */
		};

		/* node '/mcos/mco2' defined in zephyr\dts\arm\st\f4\stm32f4.dtsi:104 */
		mco2: mco2 {
			compatible = "st,stm32-clock-mco"; /* in zephyr\dts\arm\st\f4\stm32f4.dtsi:105 */
			status = "disabled";               /* in zephyr\dts\arm\st\f4\stm32f4.dtsi:106 */
		};
	};

	/* node '/power@40007000' defined in zephyr\dts\arm\st\f4\stm32f4.dtsi:603 */
	pwr: power@40007000 {
		compatible = "st,stm32-pwr"; /* in zephyr\dts\arm\st\f4\stm32f4.dtsi:604 */
		reg = < 0x40007000 0x400 >;  /* in zephyr\dts\arm\st\f4\stm32f4.dtsi:605 */
		status = "disabled";         /* in zephyr\dts\arm\st\f4\stm32f4.dtsi:606 */
		wkup-pins-nb = < 0x1 >;      /* in zephyr\dts\arm\st\f4\stm32f4.dtsi:608 */
		#address-cells = < 0x1 >;    /* in zephyr\dts\arm\st\f4\stm32f4.dtsi:610 */
		#size-cells = < 0x0 >;       /* in zephyr\dts\arm\st\f4\stm32f4.dtsi:611 */

		/* node '/power@40007000/wkup-pin@1' defined in zephyr\dts\arm\st\f4\stm32f4.dtsi:613 */
		wkup-pin@1 {
			reg = < 0x1 >;                   /* in zephyr\dts\arm\st\f4\stm32f4.dtsi:614 */
			wkup-gpios = < &gpioa 0x0 0x1 >; /* in zephyr\dts\arm\st\f4\stm32f4.dtsi:615 */
		};
	};

	/* node '/dietemp' defined in zephyr\dts\arm\st\f4\stm32f4.dtsi:619 */
	die_temp: dietemp {
		compatible = "st,stm32-temp-cal"; /* in zephyr\dts\arm\st\f4\stm32f4.dtsi:620 */
		ts-cal1-addr = < 0x1fff7a2c >;    /* in zephyr\dts\arm\st\f4\stm32f4.dtsi:621 */
		ts-cal2-addr = < 0x1fff7a2e >;    /* in zephyr\dts\arm\st\f4\stm32f4.dtsi:622 */
		ts-cal1-temp = < 0x1e >;          /* in zephyr\dts\arm\st\f4\stm32f4.dtsi:623 */
		ts-cal2-temp = < 0x6e >;          /* in zephyr\dts\arm\st\f4\stm32f4.dtsi:624 */
		ts-cal-vrefanalog = < 0xce4 >;    /* in zephyr\dts\arm\st\f4\stm32f4.dtsi:625 */
		status = "disabled";              /* in zephyr\dts\arm\st\f4\stm32f4.dtsi:627 */
		io-channels = < &adc1 0x12 >;     /* in zephyr\dts\arm\st\f4\stm32f446.dtsi:200 */
	};

	/* node '/vref' defined in zephyr\dts\arm\st\f4\stm32f4.dtsi:630 */
	vref: vref {
		compatible = "st,stm32-vref";      /* in zephyr\dts\arm\st\f4\stm32f4.dtsi:631 */
		vrefint-cal-addr = < 0x1fff7a2a >; /* in zephyr\dts\arm\st\f4\stm32f4.dtsi:632 */
		vrefint-cal-mv = < 0xce4 >;        /* in zephyr\dts\arm\st\f4\stm32f4.dtsi:633 */
		io-channels = < &adc1 0x11 >;      /* in zephyr\dts\arm\st\f4\stm32f4.dtsi:634 */
		status = "disabled";               /* in zephyr\dts\arm\st\f4\stm32f4.dtsi:635 */
	};

	/* node '/vbat' defined in zephyr\dts\arm\st\f4\stm32f4.dtsi:638 */
	vbat: vbat {
		compatible = "st,stm32-vbat"; /* in zephyr\dts\arm\st\f4\stm32f4.dtsi:639 */
		ratio = < 0x4 >;              /* in zephyr\dts\arm\st\f4\stm32f4.dtsi:640 */
		io-channels = < &adc1 0x12 >; /* in zephyr\dts\arm\st\f4\stm32f4.dtsi:641 */
		status = "disabled";          /* in zephyr\dts\arm\st\f4\stm32f4.dtsi:642 */
	};

	/* node '/otgfs_phy' defined in zephyr\dts\arm\st\f4\stm32f4.dtsi:645 */
	otgfs_phy: otgfs_phy {
		compatible = "usb-nop-xceiv"; /* in zephyr\dts\arm\st\f4\stm32f4.dtsi:646 */
		#phy-cells = < 0x0 >;         /* in zephyr\dts\arm\st\f4\stm32f4.dtsi:647 */
		phandle = < 0x13 >;           /* in zephyr\dts\arm\st\f4\stm32f4.dtsi:322 */
	};

	/* node '/smbus1' defined in zephyr\dts\arm\st\f4\stm32f4.dtsi:650 */
	smbus1: smbus1 {
		compatible = "st,stm32-smbus"; /* in zephyr\dts\arm\st\f4\stm32f4.dtsi:651 */
		#address-cells = < 0x1 >;      /* in zephyr\dts\arm\st\f4\stm32f4.dtsi:652 */
		#size-cells = < 0x0 >;         /* in zephyr\dts\arm\st\f4\stm32f4.dtsi:653 */
		i2c = < &i2c1 >;               /* in zephyr\dts\arm\st\f4\stm32f4.dtsi:654 */
		status = "disabled";           /* in zephyr\dts\arm\st\f4\stm32f4.dtsi:655 */
	};

	/* node '/smbus2' defined in zephyr\dts\arm\st\f4\stm32f4.dtsi:658 */
	smbus2: smbus2 {
		compatible = "st,stm32-smbus"; /* in zephyr\dts\arm\st\f4\stm32f4.dtsi:659 */
		#address-cells = < 0x1 >;      /* in zephyr\dts\arm\st\f4\stm32f4.dtsi:660 */
		#size-cells = < 0x0 >;         /* in zephyr\dts\arm\st\f4\stm32f4.dtsi:661 */
		i2c = < &i2c2 >;               /* in zephyr\dts\arm\st\f4\stm32f4.dtsi:662 */
		status = "disabled";           /* in zephyr\dts\arm\st\f4\stm32f4.dtsi:663 */
	};

	/* node '/smbus3' defined in zephyr\dts\arm\st\f4\stm32f4.dtsi:666 */
	smbus3: smbus3 {
		compatible = "st,stm32-smbus"; /* in zephyr\dts\arm\st\f4\stm32f4.dtsi:667 */
		#address-cells = < 0x1 >;      /* in zephyr\dts\arm\st\f4\stm32f4.dtsi:668 */
		#size-cells = < 0x0 >;         /* in zephyr\dts\arm\st\f4\stm32f4.dtsi:669 */
		i2c = < &i2c3 >;               /* in zephyr\dts\arm\st\f4\stm32f4.dtsi:670 */
		status = "disabled";           /* in zephyr\dts\arm\st\f4\stm32f4.dtsi:671 */
	};

	/* node '/otghs_fs_phy' defined in zephyr\dts\arm\st\f4\stm32f446.dtsi:203 */
	otghs_fs_phy: otghs_fs_phy {
		compatible = "usb-nop-xceiv"; /* in zephyr\dts\arm\st\f4\stm32f446.dtsi:204 */
		#phy-cells = < 0x0 >;         /* in zephyr\dts\arm\st\f4\stm32f446.dtsi:205 */
		phandle = < 0x1b >;           /* in zephyr\dts\arm\st\f4\stm32f446.dtsi:102 */
	};

	/* node '/connector' defined in zephyr\boards\st\nucleo_f446re\arduino_r3_connector.dtsi:10 */
	arduino_header: connector {
		compatible = "arduino-header-r3";          /* in zephyr\boards\st\nucleo_f446re\arduino_r3_connector.dtsi:11 */
		#gpio-cells = < 0x2 >;                     /* in zephyr\boards\st\nucleo_f446re\arduino_r3_connector.dtsi:12 */
		gpio-map-mask = < 0xffffffff 0xffffffc0 >; /* in zephyr\boards\st\nucleo_f446re\arduino_r3_connector.dtsi:13 */
		gpio-map-pass-thru = < 0x0 0x3f >;         /* in zephyr\boards\st\nucleo_f446re\arduino_r3_connector.dtsi:14 */
		gpio-map = < 0x0 0x0 &gpioa 0x0 0x0 >,
		           < 0x1 0x0 &gpioa 0x1 0x0 >,
		           < 0x2 0x0 &gpioa 0x4 0x0 >,
		           < 0x3 0x0 &gpiob 0x0 0x0 >,
		           < 0x4 0x0 &gpioc 0x1 0x0 >,
		           < 0x5 0x0 &gpioc 0x0 0x0 >,
		           < 0x6 0x0 &gpioa 0x3 0x0 >,
		           < 0x7 0x0 &gpioa 0x2 0x0 >,
		           < 0x8 0x0 &gpioa 0xa 0x0 >,
		           < 0x9 0x0 &gpiob 0x3 0x0 >,
		           < 0xa 0x0 &gpiob 0x5 0x0 >,
		           < 0xb 0x0 &gpiob 0x4 0x0 >,
		           < 0xc 0x0 &gpiob 0xa 0x0 >,
		           < 0xd 0x0 &gpioa 0x8 0x0 >,
		           < 0xe 0x0 &gpioa 0x9 0x0 >,
		           < 0xf 0x0 &gpioc 0x7 0x0 >,
		           < 0x10 0x0 &gpiob 0x6 0x0 >,
		           < 0x11 0x0 &gpioa 0x7 0x0 >,
		           < 0x12 0x0 &gpioa 0x6 0x0 >,
		           < 0x13 0x0 &gpioa 0x5 0x0 >,
		           < 0x14 0x0 &gpiob 0x9 0x0 >,
		           < 0x15 0x0 &gpiob 0x8 0x0 >;    /* in zephyr\boards\st\nucleo_f446re\arduino_r3_connector.dtsi:15 */
	};

	/* node '/st-morpho-header' defined in zephyr\boards\st\nucleo_f446re\st_morpho_connector.dtsi:10 */
	st_morpho_header: st-morpho-header {
		compatible = "st-morpho-header";        /* in zephyr\boards\st\nucleo_f446re\st_morpho_connector.dtsi:11 */
		#gpio-cells = < 0x2 >;                  /* in zephyr\boards\st\nucleo_f446re\st_morpho_connector.dtsi:12 */
		gpio-map-mask = < 0xff 0x0 >;           /* in zephyr\boards\st\nucleo_f446re\st_morpho_connector.dtsi:13 */
		gpio-map-pass-thru = < 0x0 0x7f >;      /* in zephyr\boards\st\nucleo_f446re\st_morpho_connector.dtsi:14 */
		gpio-map = < 0x0 0x0 &gpioc 0xa 0x0 >,
		           < 0x1 0x0 &gpioc 0xb 0x0 >,
		           < 0x2 0x0 &gpioc 0xc 0x0 >,
		           < 0x3 0x0 &gpiod 0x2 0x0 >,
		           < 0xc 0x0 &gpioa 0xd 0x0 >,
		           < 0xe 0x0 &gpioa 0xe 0x0 >,
		           < 0x10 0x0 &gpioa 0xf 0x0 >,
		           < 0x14 0x0 &gpiob 0x7 0x0 >,
		           < 0x16 0x0 &gpioc 0xd 0x0 >,
		           < 0x18 0x0 &gpioc 0xe 0x0 >,
		           < 0x1a 0x0 &gpioc 0xf 0x0 >,
		           < 0x1b 0x0 &gpioa 0x0 0x0 >,
		           < 0x1c 0x0 &gpioh 0x0 0x0 >,
		           < 0x1d 0x0 &gpioa 0x1 0x0 >,
		           < 0x1e 0x0 &gpioh 0x1 0x0 >,
		           < 0x1f 0x0 &gpioa 0x4 0x0 >,
		           < 0x21 0x0 &gpiob 0x0 0x0 >,
		           < 0x22 0x0 &gpioc 0x2 0x0 >,
		           < 0x23 0x0 &gpioc 0x1 0x0 >,
		           < 0x24 0x0 &gpioc 0x3 0x0 >,
		           < 0x25 0x0 &gpioc 0x0 0x0 >,
		           < 0x48 0x0 &gpioc 0x9 0x0 >,
		           < 0x49 0x0 &gpioc 0x8 0x0 >,
		           < 0x4a 0x0 &gpiob 0x8 0x0 >,
		           < 0x4b 0x0 &gpioc 0x6 0x0 >,
		           < 0x4c 0x0 &gpiob 0x9 0x0 >,
		           < 0x4d 0x0 &gpioc 0x5 0x0 >,
		           < 0x52 0x0 &gpioa 0x5 0x0 >,
		           < 0x53 0x0 &gpioa 0xc 0x0 >,
		           < 0x54 0x0 &gpioa 0x6 0x0 >,
		           < 0x55 0x0 &gpioa 0xb 0x0 >,
		           < 0x56 0x0 &gpioa 0x7 0x0 >,
		           < 0x57 0x0 &gpiob 0xc 0x0 >,
		           < 0x58 0x0 &gpiob 0x6 0x0 >,
		           < 0x5a 0x0 &gpioc 0x7 0x0 >,
		           < 0x5c 0x0 &gpioa 0x9 0x0 >,
		           < 0x5d 0x0 &gpiob 0x2 0x0 >,
		           < 0x5e 0x0 &gpioa 0x8 0x0 >,
		           < 0x5f 0x0 &gpiob 0x1 0x0 >,
		           < 0x60 0x0 &gpiob 0xa 0x0 >,
		           < 0x61 0x0 &gpiob 0xf 0x0 >,
		           < 0x62 0x0 &gpiob 0x4 0x0 >,
		           < 0x63 0x0 &gpiob 0xe 0x0 >,
		           < 0x64 0x0 &gpiob 0x5 0x0 >,
		           < 0x65 0x0 &gpiob 0xd 0x0 >,
		           < 0x66 0x0 &gpiob 0x3 0x0 >,
		           < 0x68 0x0 &gpioa 0xa 0x0 >,
		           < 0x69 0x0 &gpioc 0x4 0x0 >,
		           < 0x6a 0x0 &gpioa 0x2 0x0 >,
		           < 0x6c 0x0 &gpioa 0x3 0x0 >; /* in zephyr\boards\st\nucleo_f446re\st_morpho_connector.dtsi:15 */
	};

	/* node '/leds' defined in zephyr\boards\st\nucleo_f446re\nucleo_f446re.dts:26 */
	leds: leds {
		compatible = "gpio-leds"; /* in zephyr\boards\st\nucleo_f446re\nucleo_f446re.dts:27 */

		/* node '/leds/led_2' defined in zephyr\boards\st\nucleo_f446re\nucleo_f446re.dts:29 */
		green_led_2: led_2 {
			gpios = < &gpioa 0x5 0x0 >; /* in zephyr\boards\st\nucleo_f446re\nucleo_f446re.dts:30 */
			label = "User LD2";         /* in zephyr\boards\st\nucleo_f446re\nucleo_f446re.dts:31 */
		};
	};

	/* node '/pwmleds' defined in zephyr\boards\st\nucleo_f446re\nucleo_f446re.dts:35 */
	pwmleds {
		compatible = "pwm-leds"; /* in zephyr\boards\st\nucleo_f446re\nucleo_f446re.dts:36 */

		/* node '/pwmleds/green_pwm_led' defined in zephyr\boards\st\nucleo_f446re\nucleo_f446re.dts:38 */
		green_pwm_led: green_pwm_led {
			pwms = < &pwm2 0x1 0x1312d00 0x0 >; /* in zephyr\boards\st\nucleo_f446re\nucleo_f446re.dts:39 */
		};
	};

	/* node '/gpio_keys' defined in zephyr\boards\st\nucleo_f446re\nucleo_f446re.dts:43 */
	gpio_keys {
		compatible = "gpio-keys"; /* in zephyr\boards\st\nucleo_f446re\nucleo_f446re.dts:44 */

		/* node '/gpio_keys/button' defined in zephyr\boards\st\nucleo_f446re\nucleo_f446re.dts:46 */
		user_button: button {
			label = "User";             /* in zephyr\boards\st\nucleo_f446re\nucleo_f446re.dts:47 */
			gpios = < &gpioc 0xd 0x1 >; /* in zephyr\boards\st\nucleo_f446re\nucleo_f446re.dts:48 */
			zephyr,code = < 0xb >;      /* in zephyr\boards\st\nucleo_f446re\nucleo_f446re.dts:49 */
		};
	};
};
